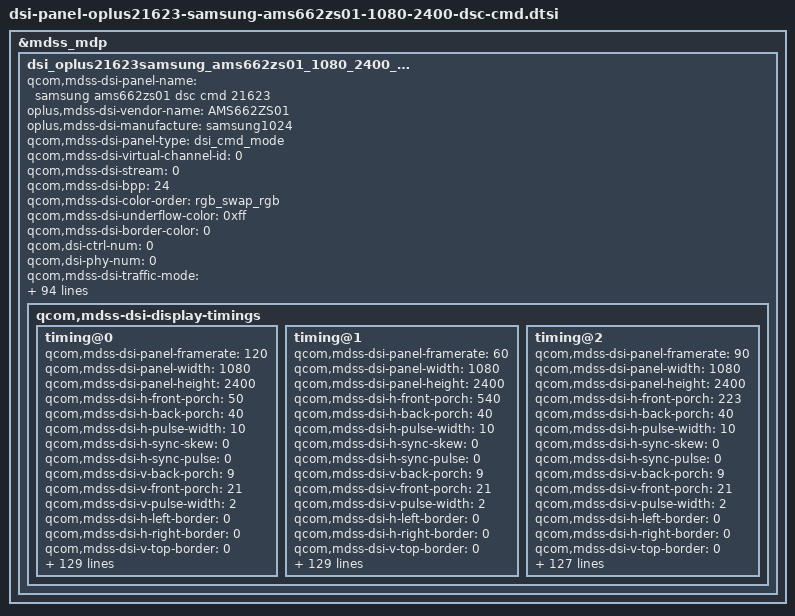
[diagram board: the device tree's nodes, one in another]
&mdss_mdp {
	dsi_oplus21623samsung_ams662zs01_1080_2400_cmd: qcom,mdss_dsi_oplus21623samsung_ams662zs01_1080_2400_cmd {
		qcom,mdss-dsi-panel-name = "samsung ams662zs01 dsc cmd 21623";
		oplus,mdss-dsi-vendor-name = "AMS662ZS01";
		oplus,mdss-dsi-manufacture = "samsung1024";
		qcom,mdss-dsi-panel-type = "dsi_cmd_mode";
		qcom,mdss-dsi-virtual-channel-id = <0>;
		qcom,mdss-dsi-stream = <0>;
		qcom,mdss-dsi-bpp = <24>;
		qcom,mdss-dsi-color-order = "rgb_swap_rgb";
		qcom,mdss-dsi-underflow-color = <0xff>;
		qcom,mdss-dsi-border-color = <0>;
		qcom,dsi-ctrl-num = <0>;
		qcom,dsi-phy-num = <0>;
		qcom,mdss-dsi-traffic-mode = "non_burst_sync_event";
		qcom,mdss-dsi-lane-map = "lane_map_0123";
		qcom,mdss-dsi-bllp-eof-power-mode;
		qcom,mdss-dsi-bllp-power-mode;
		qcom,mdss-dsi-lane-0-state;
		qcom,mdss-dsi-lane-1-state;
		qcom,mdss-dsi-lane-2-state;
		qcom,mdss-dsi-lane-3-state;
		qcom,mdss-dsi-dma-trigger = "trigger_sw";
		qcom,mdss-dsi-mdp-trigger = "none";
		qcom,mdss-dsi-reset-sequence = <1 10>, <0 10>, <1 10>;

		qcom,mdss-dsi-te-pin-select = <1>;
		qcom,mdss-dsi-te-dcs-command = <1>;
		qcom,mdss-dsi-te-check-enable;
		qcom,mdss-dsi-te-using-te-pin;
		qcom,mdss-dsi-lp11-init;
		qcom,mdss-dsi-wr-mem-start = <0x2c>;
		qcom,mdss-dsi-wr-mem-continue = <0x3c>;
		qcom,mdss-dsi-panel-hdr-enabled;
		qcom,mdss-dsi-panel-hdr-color-primaries = <15635 16450 34000 16000 13250 34500 7500 3000>;
		qcom,mdss-dsi-panel-peak-brightness = <5400000>;
		qcom,mdss-dsi-panel-blackness-level = <2000>;
		qcom,mdss-pan-physical-width-dimension = <70>;
		qcom,mdss-pan-physical-height-dimension = <153>;
		qcom,esd-check-enabled;
		qcom,mdss-dsi-panel-status-check-mode = "reg_read";
		qcom,mdss-dsi-panel-status-command = [06 01 00 01 05 00 02 0A 00
							06 01 00 01 05 00 02 05 00
							06 01 00 01 05 00 02 03 00
							06 01 00 01 05 00 02 0e 00];
		qcom,mdss-dsi-panel-status-command-state = "dsi_lp_mode";
		qcom,mdss-dsi-panel-status-value = <0x9f 0x00 0x01 0x80>;
		qcom,mdss-dsi-panel-status-read-length = <1 1 1 1>;
//		oplus,esd-err-flag-check-enabled;
		oplus,esd-err-flag-gpio = <&tlmm 100 0>;
		oplus,esd-err-trigger-polarity = <1>;
		qcom,dynamic-mode-switch-enabled;
		qcom,dynamic-mode-switch-type = "dynamic-resolution-switch-immediate";
		qcom,mdss-dsi-display-timings {
			timing@0 {
				qcom,mdss-dsi-panel-framerate = <120>;
//				qcom,mdss-dsi-panel-clockrate = <830000000>;
				qcom,mdss-dsi-panel-width = <1080>;
				qcom,mdss-dsi-panel-height = <2400>;
				qcom,mdss-dsi-h-front-porch = <50>;
				qcom,mdss-dsi-h-back-porch = <40>;
				qcom,mdss-dsi-h-pulse-width = <10>;
				qcom,mdss-dsi-h-sync-skew = <0>;
				qcom,mdss-dsi-h-sync-pulse = <0>;
				qcom,mdss-dsi-v-back-porch = <9>;
				qcom,mdss-dsi-v-front-porch = <21>;
				qcom,mdss-dsi-v-pulse-width = <2>;
				qcom,mdss-dsi-h-left-border = <0>;
				qcom,mdss-dsi-h-right-border = <0>;
				qcom,mdss-dsi-v-top-border = <0>;
				qcom,mdss-dsi-v-bottom-border = <0>;
				qcom,mdss-dsi-panel-jitter = <0x4 0x1>;

				oplus,fod-on-vblank = <0>;
				oplus,fod-off-vblank = <1>;
				qcom,mdss-dsi-timing-switch-command = [
					//120hz Transition
					39 01 00 00 00 00 03 F0 5A 5A
					39 01 00 00 00 00 03 60 08 00
					39 01 00 00 00 00 02 F7 0F
					39 01 00 00 00 00 03 F0 A5 A5
				];
				qcom,mdss-dsi-fps-switch-command = [
					39 01 00 00 00 00 03 F0 5A 5A
                                        39 01 00 00 00 00 03 B0 28 F2
                                        39 01 00 00 00 00 02 F2 CE
                                        39 01 00 00 00 00 04 B0 01 B4 65
                                        39 01 00 00 00 00 21 65 09 70 09 28 09 03 08 98 08 2C 07 BF 06 EA 06 12 05 3A 04 62 03 8B 02 B2 01 6D 00 28 00 28 00 28 
                                        39 01 00 00 00 00 04 B0 00 28 F2
                                        39 01 00 00 00 00 02 F2 C6
                                        39 01 00 00 00 00 03 60 08 00
                                        39 01 00 00 00 00 03 B0 08 F2
                                        39 01 00 00 00 00 02 F2 04
                                        39 01 00 00 00 00 02 F7 0F
                                        39 01 00 00 00 00 03 F0 A5 A5
				];
				qcom,mdss-dsi-on-command = [
					//DSC Setting
					39 01 00 00 00 00 81 9E
					11 00 00 89 30 80 09 60
					04 38 00 1E 02 1C 02 1C
					02 00 02 0E 00 20 02 E3
					00 07 00 0C 03 50 03 64
					18 00 10 F0 03 0C 20 00
					06 0B 0B 33 0E 1C 2A 38
					46 54 62 69 70 77 79 7B
					7D 7E 01 02 01 00 09 40
					09 BE 19 FC 19 FA 19 F8
					1A 38 1A 78 1A B6 2A F6
					2B 34 2B 74 3B 74 6B F4
					00 00 00 00 00 00 00 00
					00 00 00 00 00 00 00 00
					00 00 00 00 00 00 00 00
					00 00 00 00 00 00 00 00
					00 00 00 00 00 00 00 00
					39 01 00 00 00 00 02 C2 14
					39 01 00 00 00 00 02 9D 01
					//Sleep Out(11h)
					05 01 00 00 79 00 01 11
					//TE ON
					39 01 00 00 00 00 02 35 00
					//CASET/PASET Setting
					39 01 00 00 00 00 05 2A 00 00 04 37
					39 01 00 00 00 00 05 2B 00 00 09 5F
					//FQ CON Setting
					39 01 00 00 00 00 03 F0 5A 5A
					39 01 00 00 00 00 03 B0 27 F2
					39 01 00 00 00 00 02 F2 00
					39 01 00 00 00 00 03 F0 A5 A5
					//Frequency Setting
					39 01 00 00 00 00 03 F0 5A 5A
					39 01 00 00 00 00 03 60 08 00
					39 01 00 00 00 00 02 F7 0F
					39 01 00 00 00 00 03 F0 A5 A5
					/*OSC*/
					//39 01 00 00 00 00 03 F0 5A 5A
					//39 01 00 00 00 00 03 FC 5A 5A
					//39 01 00 00 00 00 03 B0 66 C5
					//39 01 00 00 00 00 03 C5 00 8C
					//39 01 00 00 00 00 03 B0 2A C5
					//39 01 00 00 00 00 05 C5 0D 10 80 45
					//39 01 00 00 00 00 03 B0 2E C5
					//39 01 00 00 00 00 03 C5 73 64
					//39 01 00 00 00 00 03 F0 A5 A5
					//39 01 00 00 00 00 03 FC A5 A5
					//BACKLIGHT
					39 01 00 00 00 00 02 53 20    //1 frame
				];

				qcom,mdss-dsi-off-command= [
					/* AOD off */
					39 01 00 00 00 00 03 F0 5A 5A
					15 01 00 00 00 00 02 91 02
					15 01 00 00 00 00 02 53 20
					39 01 00 00 00 00 03 F0 A5 A5
					05 01 00 00 0B 00 01 28
					05 01 00 00 79 00 01 10];
				qcom,mdss-dsi-post-on-backlight = [
					/* Display On */
					05 01 00 00 00 00 01 29
				];
				qcom,mdss-dsi-hbm-on-command = [
					39 01 00 00 00 00 03 F0 5A 5A
					39 01 00 00 0A 00 03 51 07 FF
					39 01 00 00 00 00 03 91 02 00
					39 01 00 00 00 00 03 B0 02 90
					39 01 00 00 00 00 02 90 1C
					/* HBM Mode ON */
					39 01 00 00 00 00 02 53 E0
					39 01 00 00 00 00 03 51 0F FF
					39 01 00 00 00 00 03 F0 A5 A5
				];
				qcom,mdss-dsi-normal-hbm-on-command = [
					39 01 00 00 00 00 03 F0 5A 5A
					39 01 00 00 0A 00 03 51 07 FF
					39 01 00 00 00 00 03 91 02 00
					39 01 00 00 00 00 03 B0 02 90
					39 01 00 00 00 00 02 90 1C
					/* HBM Mode ON */
					39 01 00 00 00 00 02 53 E0
					39 01 00 00 00 00 03 51 0F FF
					39 01 00 00 00 00 03 F0 A5 A5
				];
				qcom,mdss-dsi-hbm-off-command = [
					39 01 00 00 00 00 03 F0 5A 5A
					15 01 00 00 00 00 02 53 20
					39 01 00 00 0A 00 03 51 07 FF
					39 01 00 00 00 00 03 91 02 01
					39 01 00 00 00 00 03 B0 02 90
					39 01 00 00 00 00 02 90 18
					39 01 00 00 00 00 03 F0 A5 A5
				];
				qcom,mdss-dsi-aod-hbm-on-command = [
					39 01 00 00 00 00 03 F0 5A 5A
					15 01 00 00 00 00 02 91 02
					39 01 00 00 00 00 02 53 20
					39 01 00 00 00 00 03 F0 A5 A5
					39 01 00 00 00 00 03 F0 5A 5A
					39 01 00 00 0A 00 03 51 07 FF
					39 01 00 00 00 00 03 91 02 00
					39 01 00 00 00 00 03 B0 02 90
					39 01 00 00 00 00 02 90 1C
					/* HBM Mode ON */
					39 01 00 00 00 00 02 53 E0
					39 01 00 00 00 00 03 51 0F FF
					39 01 00 00 00 00 03 F0 A5 A5
				];
				qcom,mdss-dsi-aod-hbm-off-command = [
					39 01 00 00 00 00 03 F0 5A 5A
					15 01 00 00 00 00 02 91 02 
					15 01 00 00 00 00 02 53 20
					39 01 00 00 00 00 03 F0 A5 A5
					39 01 00 00 00 00 03 F0 5A 5A
					15 01 00 00 00 00 02 53 20
					39 01 00 00 0A 00 03 51 07 FF
					39 01 00 00 00 00 03 91 02 01
					39 01 00 00 00 00 03 B0 02 90
					39 01 00 00 00 00 02 90 18
					39 01 00 00 00 00 03 F0 A5 A5
				];
				qcom,mdss-dsi-aod-high-mode-command = [
					/* AOD 50nit */
					39 01 00 00 00 00 03 F0 5A 5A
					15 01 00 00 00 00 02 91 01
					15 01 00 00 00 00 02 53 24
					15 01 00 00 00 00 02 BB 1D
					39 01 00 00 00 00 03 F0 A5 A5
				];
				qcom,mdss-dsi-aod-low-mode-command = [
					/* AOD 10nit */
					39 01 00 00 00 00 03 F0 5A 5A
					15 01 00 00 00 00 02 91 01
					15 01 00 00 00 00 02 53 25
					15 01 00 00 00 00 02 BB 1D
					39 01 00 00 00 00 03 F0 A5 A5
				];
				qcom,mdss-dsi-lp1-command = [
					//05 01 00 00 25 00 01 28
					/*AOD on */
					39 01 00 00 00 00 03 F0 5A 5A
					15 01 00 00 00 00 02 91 01
					15 01 00 00 00 00 02 53 24
					15 01 00 00 00 00 02 BB 1D
					39 01 00 00 00 00 03 F0 A5 A5
				];
				qcom,mdss-dsi-nolp-command = [
					/* AOD off to normal*/
					39 01 00 00 00 00 03 F0 5A 5A
					15 01 00 00 00 00 02 91 02
					15 01 00 00 00 00 02 53 20
					39 01 00 00 00 00 03 F0 A5 A5
				];
				qcom,mdss-dsi-seed-off-command = [
					/* CRC OFF */
					39 01 00 00 00 00 03 F0 5A 5A
 					15 01 00 00 00 00 02 5D 00
 					15 01 00 00 00 00 02 62 01
 					39 01 00 00 00 00 03 F0 A5 A5
				];
				qcom,mdss-dsi-seed-3-command = [
					39 01 00 00 00 00 03 F0 5A 5A
					39 01 00 00 00 00 03 B0 03 8F
					39 01 00 00 00 00 02 8F 25
					39 01 00 00 00 00 03 B0 28 F2
					39 01 00 00 00 00 02 F2 CE
					39 01 00 00 00 00 04 B0 01 18 68
					39 01 00 00 00 00 0F 68 E2 1A 1A 1A 82 04 F0 80 00 00 00 00 FF 00
					39 01 00 00 00 00 04 B0 00 28 F2
					39 01 00 00 00 00 02 F2 C6
					39 01 00 00 00 00 03 F0 A5 A5
					39 01 00 00 00 00 03 F0 5A 5A
					39 01 00 00 00 00 04 72 2C 21 00
					39 01 00 00 00 00 02 F8 00
					39 01 00 00 00 00 02 5D 06
					39 01 00 00 00 00 02 62 00
					39 01 00 00 00 00 03 B0 01 62
					39 01 00 00 00 00 16 62 D3 01 00 19 Fd 00 0B 04 E2 21 E5 E4 de 06 Ec FA FD 01 FF FF FF
					39 01 00 00 18 00 04 72 2C 01 00
					39 01 00 00 00 00 03 F0 A5 A5
				];
				qcom,mdss-dsi-seed-2-command = [
					39 01 00 00 00 00 03 F0 5A 5A
					39 01 00 00 00 00 03 B0 03 8F
					39 01 00 00 00 00 02 8F 05
					39 01 00 00 00 00 03 B0 28 F2
					39 01 00 00 00 00 02 F2 CE
					39 01 00 00 00 00 04 B0 01 18 68
					39 01 00 00 00 00 0F 68 E2 1A 1A 1A 82 04 F0 80 00 00 00 00 FF 00
					39 01 00 00 00 00 04 B0 00 28 F2
					39 01 00 00 00 00 02 F2 C6
					39 01 00 00 00 00 03 F0 A5 A5
					39 01 00 00 00 00 03 F0 5A 5A
					39 01 00 00 00 00 04 72 2C 21 00
					39 01 00 00 00 00 02 F8 00
					39 01 00 00 00 00 02 5D 06
					39 01 00 00 00 00 02 62 00
					39 01 00 00 00 00 03 B0 01 62
					39 01 00 00 00 00 16 62 FF 00 00 00 FF 00 00 00 FF 00 FF FF FF 00 FF FF FF 00 FF FF FF
					39 01 00 00 18 00 04 72 2C 01 00
					39 01 00 00 00 00 03 F0 A5 A5
				];
				qcom,mdss-dsi-seed-1-command = [
					39 01 00 00 00 00 03 F0 5A 5A
					39 01 00 00 00 00 03 B0 03 8F
					39 01 00 00 00 00 02 8F 25
					39 01 00 00 00 00 03 B0 28 F2
					39 01 00 00 00 00 02 F2 CE
					39 01 00 00 00 00 04 B0 01 18 68
					39 01 00 00 00 00 0F 68 E2 1A 1A 1A 82 04 F0 80 00 00 00 00 FF 00
					39 01 00 00 00 00 04 B0 00 28 F2
					39 01 00 00 00 00 02 F2 C6
					39 01 00 00 00 00 03 F0 A5 A5
					39 01 00 00 00 00 03 F0 5A 5A
					39 01 00 00 00 00 04 72 2C 21 00
					39 01 00 00 00 00 02 F8 00
					39 01 00 00 00 00 02 5D 06
					39 01 00 00 00 00 02 62 00
					39 01 00 00 00 00 03 B0 01 62
					39 01 00 00 00 00 16 62 D3 01 00 19 Fd 00 0B 04 E2 21 E5 E4 de 06 Ec FA FD 01 FF FF FF
					39 01 00 00 18 00 04 72 2C 01 00
					39 01 00 00 00 00 03 F0 A5 A5
				];
				qcom,mdss-dsi-seed-0-command = [
					39 01 00 00 00 00 03 F0 5A 5A
					39 01 00 00 00 00 03 B0 03 8F
					39 01 00 00 00 00 02 8F 05
					39 01 00 00 00 00 03 B0 28 F2
					39 01 00 00 00 00 02 F2 CE
					39 01 00 00 00 00 04 B0 01 18 68
					39 01 00 00 00 00 0F 68 E2 1A 1A 1A 82 04 F0 80 00 00 00 00 FF 90
					39 01 00 00 00 00 04 B0 00 28 F2
					39 01 00 00 00 00 02 F2 C6
					39 01 00 00 00 00 03 F0 A5 A5
					39 01 00 00 00 00 03 F0 5A 5A
					39 01 00 00 00 00 04 72 2C 21 00
					39 01 00 00 00 00 02 F8 00
					39 01 00 00 00 00 02 5D 06
					39 01 00 00 00 00 02 62 00
					39 01 00 00 00 00 03 B0 01 62
					39 01 00 00 00 00 16 62 E5 02 00 1E F2 04 0B 06 E5 28 F3 F7 F8 08 FF EA F4 02 FF FF FF
					39 01 00 00 18 00 04 72 2C 01 00
					39 01 00 00 00 00 03 F0 A5 A5
				];
				qcom,mdss-dsi-seed-0-switch-command = [
					39 01 00 00 00 00 03 F0 5A 5A
					39 01 00 00 00 00 03 B0 03 8F
					39 01 00 00 00 00 02 8F 05
					39 01 00 00 00 00 03 B0 28 F2
					39 01 00 00 00 00 02 F2 CE
					39 01 00 00 00 00 04 B0 01 18 68
					39 01 00 00 00 00 0F 68 E2 1A 1A 1A 82 04 F0 80 00 00 00 00 FF 00
					39 01 00 00 00 00 04 B0 00 28 F2
					39 01 00 00 00 00 02 F2 C6
					39 01 00 00 00 00 03 F0 A5 A5
					39 01 00 00 00 00 03 F0 5A 5A
					39 01 00 00 00 00 04 72 2C 21 00
					39 01 00 00 00 00 02 F8 00
					39 01 00 00 00 00 02 5D 06
					39 01 00 00 00 00 02 62 00
					39 01 00 00 00 00 03 B0 01 62
					39 01 00 00 00 00 16 62 FF 00 00 00 FF 00 00 00 FF 00 FF FF FF 00 FF FF FF 00 FA FA FF
					39 01 00 00 14 00 04 72 2C 01 00
					39 01 00 00 00 00 03 F0 A5 A5
				];
                                qcom,mdss-dsi-seed-1-switch-command = [
					39 01 00 00 00 00 03 F0 5A 5A
					39 01 00 00 00 00 03 B0 03 8F
					39 01 00 00 00 00 02 8F 25
					39 01 00 00 00 00 03 B0 28 F2
					39 01 00 00 00 00 02 F2 CE
					39 01 00 00 00 00 04 B0 01 18 68
					39 01 00 00 00 00 0F 68 E2 1A 1A 1A 82 04 F0 80 00 00 00 00 FF 00
					39 01 00 00 00 00 04 B0 00 28 F2
					39 01 00 00 00 00 02 F2 C6
					39 01 00 00 00 00 03 F0 A5 A5
					39 01 00 00 00 00 03 F0 5A 5A
					39 01 00 00 00 00 04 72 2C 21 00
					39 01 00 00 00 00 02 F8 00
					39 01 00 00 00 00 02 5D 06
					39 01 00 00 00 00 02 62 00
					39 01 00 00 00 00 03 B0 01 62
					39 01 00 00 00 00 16 62 CA 0B 06 40 E9 13 0A 03 B0 48 F2 DC C4 07 C8 E9 E9 1D FA FA FF
					39 01 00 00 14 00 04 72 2C 01 00
					39 01 00 00 00 00 03 F0 A5 A5
                                ];
                                qcom,mdss-dsi-seed-2-switch-command = [
					39 01 00 00 00 00 03 F0 5A 5A
					39 01 00 00 00 00 03 B0 03 8F
					39 01 00 00 00 00 02 8F 05
					39 01 00 00 00 00 03 B0 28 F2
					39 01 00 00 00 00 02 F2 CE
					39 01 00 00 00 00 04 B0 01 18 68
					39 01 00 00 00 00 0F 68 E2 1A 1A 1A 82 04 F0 80 00 00 00 00 FF 90
					39 01 00 00 00 00 04 B0 00 28 F2
					39 01 00 00 00 00 02 F2 C6
					39 01 00 00 00 00 03 F0 A5 A5
					39 01 00 00 00 00 03 F0 5A 5A
					39 01 00 00 00 00 04 72 2C 21 00
					39 01 00 00 00 00 02 F8 00
					39 01 00 00 00 00 02 5D 06
					39 01 00 00 00 00 02 62 00
					39 01 00 00 00 00 03 B0 01 62
					39 01 00 00 00 00 16 62 D7 02 00 1E EA 04 0D 05 C8 28 F3 F7 F8 08 FF EA F4 02 FA FA FF
					39 01 00 00 14 00 04 72 2C 01 00
					39 01 00 00 00 00 03 F0 A5 A5
                                ];
				qcom,mdss-dsi-seed-0-dc-command = [
					39 01 00 00 00 00 03 F0 5A 5A
					39 01 00 00 00 00 03 B0 03 8F
					39 01 00 00 00 00 02 8F 05
					39 01 00 00 00 00 03 B0 28 F2
					39 01 00 00 00 00 02 F2 CE
					39 01 00 00 00 00 04 B0 01 18 68
					39 01 00 00 00 00 0F 68 E2 1A 1A 1A 82 04 F0 80 00 00 00 00 FF 90
					39 01 00 00 00 00 04 B0 00 28 F2
					39 01 00 00 00 00 02 F2 C6
					39 01 00 00 00 00 03 F0 A5 A5
                                        /* SEED CRC Setting Adobe*/
                                        39 01 00 00 00 00 03 F0 5A 5A
					39 01 00 00 00 00 02 5D 06
					39 01 00 00 00 00 02 62 00
					39 01 00 00 00 00 03 B0 01 62
					39 01 00 00 00 00 16 62 FF 00 00 00 FF 00 00 00 FF 00 FF FF FF 00 FF FF FF 00 FF FF FF
                                        39 01 00 00 00 00 03 F0 A5 A5
                                ];
                                qcom,mdss-dsi-seed-1-dc-command = [
					39 01 00 00 00 00 03 F0 5A 5A
					39 01 00 00 00 00 03 B0 03 8F
					39 01 00 00 00 00 02 8F 25
					39 01 00 00 00 00 03 B0 28 F2
					39 01 00 00 00 00 02 F2 CE
					39 01 00 00 00 00 04 B0 01 18 68
					39 01 00 00 00 00 0F 68 E2 1A 1A 1A 82 04 F0 80 00 00 00 00 FF 90
					39 01 00 00 00 00 04 B0 00 28 F2
					39 01 00 00 00 00 02 F2 C6
					39 01 00 00 00 00 03 F0 A5 A5
                                        /* SEED CRC Setting SRGB*/
                                        39 01 00 00 00 00 03 F0 5A 5A
                                        39 01 00 00 00 00 02 5D 06              /* SRGB */
                                        /* SEED CRC ON */
                                        39 01 00 00 00 00 02 62 00
                                        /* SEED CRC Adobe */
                                        39 01 00 00 00 00 03 B0 01 62
					39 01 00 00 00 00 16 62 CA 0B 06 40 E9 13 0A 03 B0 48 F2 DC C4 07 C8 E9 E9 1D FF FF FF
                                        39 01 00 00 00 00 03 F0 A5 A5
                                ];
                                qcom,mdss-dsi-seed-2-dc-command = [
					39 01 00 00 00 00 03 F0 5A 5A
					39 01 00 00 00 00 03 B0 03 8F
					39 01 00 00 00 00 02 8F 05
					39 01 00 00 00 00 03 B0 28 F2
					39 01 00 00 00 00 02 F2 CE
					39 01 00 00 00 00 04 B0 01 18 68
					39 01 00 00 00 00 0F 68 E2 1A 1A 1A 82 04 F0 80 00 00 00 00 FF 90
					39 01 00 00 00 00 04 B0 00 28 F2
					39 01 00 00 00 00 02 F2 C6
					39 01 00 00 00 00 03 F0 A5 A5
                                        /* SEED CRC Setting P3*/
                                        39 01 00 00 00 00 03 F0 5A 5A
					39 01 00 00 00 00 02 5D 06
					39 01 00 00 00 00 02 62 00
					39 01 00 00 00 00 03 B0 01 62
					39 01 00 00 00 00 16 62 D7 02 00 1E EA 04 0D 05 C8 28 F3 F7 F8 08 FF EA F4 02 FF FF FF
                                        39 01 00 00 00 00 03 F0 A5 A5
                                ];
				qcom,mdss-dsi-seed-0-dc-switch-command = [
					39 01 00 00 00 00 03 F0 5A 5A
					39 01 00 00 00 00 03 B0 03 8F
					39 01 00 00 00 00 02 8F 05
					39 01 00 00 00 00 03 B0 28 F2
					39 01 00 00 00 00 02 F2 CE
					39 01 00 00 00 00 04 B0 01 18 68
					39 01 00 00 00 00 0F 68 E2 1A 1A 1A 82 04 F0 80 00 00 00 00 FF 00
					39 01 00 00 00 00 04 B0 00 28 F2
					39 01 00 00 00 00 02 F2 C6
					39 01 00 00 00 00 03 F0 A5 A5
					39 01 00 00 00 00 03 F0 5A 5A
					39 01 00 00 00 00 04 72 2C 21 00
					39 01 00 00 00 00 02 F8 00
					39 01 00 00 00 00 02 5D 06
					39 01 00 00 00 00 02 62 00
					39 01 00 00 00 00 03 B0 01 62
					39 01 00 00 00 00 16 62 FF 00 00 00 FF 00 00 00 FF 00 FF FF FF 00 FF FF FF 00 FF FF FF
					39 01 00 00 14 00 04 72 2C 01 00
					39 01 00 00 00 00 03 F0 A5 A5
                                ];
                                qcom,mdss-dsi-seed-1-dc-switch-command = [
					39 01 00 00 00 00 03 F0 5A 5A
					39 01 00 00 00 00 03 B0 03 8F
					39 01 00 00 00 00 02 8F 25
					39 01 00 00 00 00 03 B0 28 F2
					39 01 00 00 00 00 02 F2 CE
					39 01 00 00 00 00 04 B0 01 18 68
					39 01 00 00 00 00 0F 68 E2 1A 1A 1A 82 04 F0 80 00 00 00 00 FF 00
					39 01 00 00 00 00 04 B0 00 28 F2
					39 01 00 00 00 00 02 F2 C6
					39 01 00 00 00 00 03 F0 A5 A5
					39 01 00 00 00 00 03 F0 5A 5A
					39 01 00 00 00 00 04 72 2C 21 00
					39 01 00 00 00 00 02 F8 00
					39 01 00 00 00 00 02 5D 06
					39 01 00 00 00 00 02 62 00
					39 01 00 00 00 00 03 B0 01 62
					39 01 00 00 00 00 16 62 CA 0B 06 40 E9 13 0A 03 B0 48 F2 DC C4 07 C8 E9 E9 1D FF FF FF
					39 01 00 00 14 00 04 72 2C 01 00
					39 01 00 00 00 00 03 F0 A5 A5
                                ];
                                qcom,mdss-dsi-seed-2-dc-switch-command = [
					39 01 00 00 00 00 03 F0 5A 5A
					39 01 00 00 00 00 03 B0 03 8F
					39 01 00 00 00 00 02 8F 05
					39 01 00 00 00 00 03 B0 28 F2
					39 01 00 00 00 00 02 F2 CE
					39 01 00 00 00 00 04 B0 01 18 68
					39 01 00 00 00 00 0F 68 E2 1A 1A 1A 82 04 F0 80 00 00 00 00 FF 90
					39 01 00 00 00 00 04 B0 00 28 F2
					39 01 00 00 00 00 02 F2 C6
					39 01 00 00 00 00 03 F0 A5 A5
					39 01 00 00 00 00 03 F0 5A 5A
					39 01 00 00 00 00 04 72 2C 21 00
					39 01 00 00 00 00 02 F8 00
					39 01 00 00 00 00 02 5D 06
					39 01 00 00 00 00 02 62 00
					39 01 00 00 00 00 03 B0 01 62
					39 01 00 00 00 00 16 62 D7 02 00 1E EA 04 0D 05 C8 28 F3 F7 F8 08 FF EA F4 02 FF FF FF
					39 01 00 00 14 00 04 72 2C 01 00
					39 01 00 00 00 00 03 F0 A5 A5
                                ];
				qcom,mdss-dsi-hbm-enter-switch-command = [
					39 01 00 00 00 00 03 F0 5A 5A
                                        39 01 00 00 0A 00 03 51 07 FF
                                        39 01 00 00 00 00 03 91 02 00
                                        39 01 00 00 00 00 03 B0 02 90
                                        39 01 00 00 00 00 02 90 1C
                                        /* HBM Mode ON */
                                        39 01 00 00 00 00 02 53 E0
                                        39 01 00 00 00 00 03 F0 A5 A5
				];
				qcom,mdss-dsi-hbm-exit-switch-command = [
					39 01 00 00 00 00 03 F0 5A 5A
                                        15 01 00 00 00 00 02 53 20
                                        39 01 00 00 0A 00 03 51 07 FF
                                        39 01 00 00 00 00 03 91 02 01
                                        39 01 00 00 00 00 03 B0 02 90
                                        39 01 00 00 00 00 02 90 18
                                        39 01 00 00 00 00 03 F0 A5 A5
				];
				qcom,mdss-dsi-osc-clk-mode0-command = [
					/*OSC 415 + 180.3*/
					39 01 00 00 00 00 03 F0 5A 5A
					39 01 00 00 00 00 03 FC 5A 5A
					39 01 00 00 00 00 03 B0 2A C5
					39 01 00 00 00 00 05 C5 0D 10 80 45
					39 01 00 00 00 00 03 B0 2E C5
					39 01 00 00 00 00 03 C5 6F 39
					39 01 00 00 00 00 03 F0 A5 A5
					39 01 00 00 00 00 03 FC A5 A5
				];
				qcom,mdss-dsi-osc-clk-mode1-command = [
					/*OSC 415 + 182.3*/
					39 01 00 00 00 00 03 F0 5A 5A
					39 01 00 00 00 00 03 FC 5A 5A
					39 01 00 00 00 00 03 B0 2A C5
					39 01 00 00 00 00 05 C5 0D 10 80 45
					39 01 00 00 00 00 03 B0 2E C5
					39 01 00 00 00 00 03 C5 70 74
					39 01 00 00 00 00 03 F0 A5 A5
					39 01 00 00 00 00 03 FC A5 A5
				];
				qcom,mdss-dsi-osc-clk-mode2-command = [
					/*OSC 400 + 180.3*/
					39 01 00 00 00 00 03 F0 5A 5A
					39 01 00 00 00 00 03 FC 5A 5A
					39 01 00 00 00 00 03 B0 2A C5
					39 01 00 00 00 00 05 C5 0D 10 80 45
					39 01 00 00 00 00 03 B0 2E C5
					39 01 00 00 00 00 03 C5 73 64
					39 01 00 00 00 00 03 F0 A5 A5
					39 01 00 00 00 00 03 FC A5 A5
				];
				qcom,mdss-dsi-osc-clk-mode3-command = [
					/*OSC 400 + 182.3*/
					39 01 00 00 00 00 03 F0 5A 5A
					39 01 00 00 00 00 03 FC 5A 5A
					39 01 00 00 00 00 03 B0 2A C5
					39 01 00 00 00 00 05 C5 0D 10 80 45
					39 01 00 00 00 00 03 B0 2E C5
					39 01 00 00 00 00 03 C5 74 AC
					39 01 00 00 00 00 03 F0 A5 A5
					39 01 00 00 00 00 03 FC A5 A5
				];
				qcom,mdss-dsi-timing-switch-command-state = "dsi_hs_mode";
				qcom,mdss-dsi-on-command-state = "dsi_lp_mode";
				qcom,mdss-dsi-off-command-state = "dsi_hs_mode";
				qcom,mdss-dsi-hbm-on-command-state = "dsi_hs_mode";
				qcom,mdss-dsi-hbm-off-command-state = "dsi_hs_mode";
				qcom,mdss-dsi-osc-clk-mode0-command-state = "dsi_hs_mode";
				qcom,mdss-dsi-osc-clk-mode1-command-state = "dsi_hs_mode";
				qcom,mdss-dsi-osc-clk-mode2-command-state = "dsi_hs_mode";
				qcom,mdss-dsi-osc-clk-mode3-command-state = "dsi_hs_mode";
				qcom,mdss-dsi-seed-0-command-state = "dsi_hs_mode";
				qcom,mdss-dsi-seed-1-command-state = "dsi_hs_mode";
				qcom,mdss-dsi-seed-2-command-state = "dsi_hs_mode";
				qcom,mdss-dsi-seed-3-command-state = "dsi_hs_mode";
				qcom,mdss-dsi-seed-0-dc-switch-command-state = "dsi_hs_mode";
				qcom,mdss-dsi-seed-1-dc-switch-command-state = "dsi_hs_mode";
				qcom,mdss-dsi-seed-2-dc-switch-command-state = "dsi_hs_mode";
				qcom,mdss-dsi-seed-0-dc-command-state = "dsi_hs_mode";
				qcom,mdss-dsi-seed-1-dc-command-state = "dsi_hs_mode";
				qcom,mdss-dsi-seed-2-dc-command-state = "dsi_hs_mode";
				qcom,mdss-dsi-seed-off-command-state = "dsi_hs_mode";
				qcom,mdss-dsi-seed-0-switch-command-state = "dsi_hs_mode";
				qcom,mdss-dsi-seed-1-switch-command-state = "dsi_hs_mode";
				qcom,mdss-dsi-seed-2-switch-command-state = "dsi_hs_mode";
				qcom,mdss-dsi-fps-switch-command-state = "dsi_hs_mode";
				qcom,compression-mode = "dsc";
				qcom,mdss-dsc-slice-height = <30>;
				qcom,mdss-dsc-slice-width = <540>;
				qcom,mdss-dsc-slice-per-pkt = <2>;
				qcom,mdss-dsc-bit-per-component = <8>;
				qcom,mdss-dsc-bit-per-pixel = <8>;
				qcom,mdss-dsc-block-prediction-enable;
			};

			timing@1 {
				qcom,mdss-dsi-panel-framerate = <60>;
//				qcom,mdss-dsi-panel-clockrate = <830000000>;
				qcom,mdss-dsi-panel-width = <1080>;
				qcom,mdss-dsi-panel-height = <2400>;
				qcom,mdss-dsi-h-front-porch = <540>;
				qcom,mdss-dsi-h-back-porch = <40>;
				qcom,mdss-dsi-h-pulse-width = <10>;
				qcom,mdss-dsi-h-sync-skew = <0>;
				qcom,mdss-dsi-h-sync-pulse = <0>;
				qcom,mdss-dsi-v-back-porch = <9>;
				qcom,mdss-dsi-v-front-porch = <21>;
				qcom,mdss-dsi-v-pulse-width = <2>;
				qcom,mdss-dsi-h-left-border = <0>;
				qcom,mdss-dsi-h-right-border = <0>;
				qcom,mdss-dsi-v-top-border = <0>;
				qcom,mdss-dsi-v-bottom-border = <0>;
				qcom,mdss-dsi-panel-jitter = <0x4 0x1>;

				oplus,fod-on-vblank = <0>;
				oplus,fod-off-vblank = <1>;
				qcom,mdss-dsi-timing-switch-command = [
					//60hz Transition
                                        39 01 00 00 00 00 03 F0 5A 5A
                                        39 01 00 00 00 00 03 60 00 00
                                        39 01 00 00 00 00 02 F7 0F
                                        39 01 00 00 11 00 03 F0 A5 A5
				];
				qcom,mdss-dsi-fps-switch-command = [
					39 01 00 00 00 00 03 F0 5A 5A
                                        39 01 00 00 00 00 03 B0 28 F2
                                        39 01 00 00 00 00 02 F2 CE
                                        39 01 00 00 00 00 04 B0 01 B4 65
                                        39 01 00 00 00 00 21 65 09 70 09 28 09 03 08 98 08 2C 07 BF 06 EA 06 12 05 3A 04 62 03 8B 02 B2 01 6D 00 28 00 28 00 28
                                        39 01 00 00 00 00 04 B0 00 28 F2
                                        39 01 00 00 00 00 02 F2 C6
                                        39 01 00 00 00 00 03 60 00 00
                                        39 01 00 00 00 00 03 B0 08 F2
                                        39 01 00 00 00 00 02 F2 04
                                        39 01 00 00 00 00 02 F7 0F
                                        39 01 00 00 11 00 03 F0 A5 A5
				];
				qcom,mdss-dsi-on-command = [
					//DSC Setting
					39 01 00 00 00 00 81 9E
					11 00 00 89 30 80 09 60
					04 38 00 1E 02 1C 02 1C
					02 00 02 0E 00 20 02 E3
					00 07 00 0C 03 50 03 64
					18 00 10 F0 03 0C 20 00
					06 0B 0B 33 0E 1C 2A 38
					46 54 62 69 70 77 79 7B
					7D 7E 01 02 01 00 09 40
					09 BE 19 FC 19 FA 19 F8
					1A 38 1A 78 1A B6 2A F6
					2B 34 2B 74 3B 74 6B F4
					00 00 00 00 00 00 00 00
					00 00 00 00 00 00 00 00
					00 00 00 00 00 00 00 00
					00 00 00 00 00 00 00 00
					00 00 00 00 00 00 00 00
					39 01 00 00 00 00 02 C2 14
					39 01 00 00 00 00 02 9D 01
					//Sleep Out(11h)
					05 01 00 00 79 00 01 11
					//TE ON
					39 01 00 00 00 00 02 35 00
					//CASET/PASET Setting
					39 01 00 00 00 00 05 2A 00 00 04 37
					39 01 00 00 00 00 05 2B 00 00 09 5F
					//FQ CON Setting
					39 01 00 00 00 00 03 F0 5A 5A
					39 01 00 00 00 00 03 B0 27 F2
					39 01 00 00 00 00 02 F2 00
					39 01 00 00 00 00 03 F0 A5 A5
					//Frequency Setting
					39 01 00 00 00 00 03 F0 5A 5A
					39 01 00 00 00 00 03 60 00 00
					39 01 00 00 00 00 02 F7 0F
					39 01 00 00 00 00 03 F0 A5 A5
					/*OSC*/
					//39 01 00 00 00 00 03 F0 5A 5A
					//39 01 00 00 00 00 03 FC 5A 5A
					//39 01 00 00 00 00 03 B0 66 C5
					//39 01 00 00 00 00 03 C5 00 8C
					//39 01 00 00 00 00 03 B0 2A C5
					//39 01 00 00 00 00 05 C5 0D 10 80 45
					//39 01 00 00 00 00 03 B0 2E C5
					//39 01 00 00 00 00 03 C5 73 64
					//39 01 00 00 00 00 03 F0 A5 A5
					//39 01 00 00 00 00 03 FC A5 A5
					//BACKLIGHT
					39 01 00 00 00 00 02 53 20    //1 frame
				];

				qcom,mdss-dsi-off-command= [
					/* AOD off */
					39 01 00 00 00 00 03 F0 5A 5A
					15 01 00 00 00 00 02 91 02
					15 01 00 00 00 00 02 53 20
					39 01 00 00 00 00 03 F0 A5 A5
					05 01 00 00 0B 00 01 28
					05 01 00 00 79 00 01 10];
				qcom,mdss-dsi-post-on-backlight = [
					/* Display On */
					05 01 00 00 00 00 01 29
				];
				qcom,mdss-dsi-hbm-on-command = [
					39 01 00 00 00 00 03 F0 5A 5A
					39 01 00 00 0A 00 03 51 07 FF
					39 01 00 00 00 00 03 91 02 00
					39 01 00 00 00 00 03 B0 02 90
					39 01 00 00 00 00 02 90 1C
					/* HBM Mode ON */
					39 01 00 00 00 00 02 53 E0
					39 01 00 00 00 00 03 51 0F FF
					39 01 00 00 00 00 03 F0 A5 A5
				];
				qcom,mdss-dsi-normal-hbm-on-command = [
					39 01 00 00 00 00 03 F0 5A 5A
					39 01 00 00 14 00 03 51 07 FF
					39 01 00 00 00 00 03 91 02 00
					39 01 00 00 00 00 03 B0 02 90
					39 01 00 00 00 00 02 90 1C
					/* HBM Mode ON */
					39 01 00 00 00 00 02 53 E0
					39 01 00 00 00 00 03 51 0F FF
					39 01 00 00 00 00 03 F0 A5 A5
				];
				qcom,mdss-dsi-hbm-off-command = [
					39 01 00 00 00 00 03 F0 5A 5A
					15 01 00 00 00 00 02 53 20
					39 01 00 00 14 00 03 51 07 FF
					39 01 00 00 00 00 03 91 02 01
					39 01 00 00 00 00 03 B0 02 90
					39 01 00 00 00 00 02 90 18
					39 01 00 00 00 00 03 F0 A5 A5
				];
				qcom,mdss-dsi-aod-hbm-on-command = [
					39 01 00 00 00 00 03 F0 5A 5A
                                        15 01 00 00 00 00 02 91 02
                                        39 01 00 00 00 00 02 53 20
                                        39 01 00 00 00 00 03 F0 A5 A5
					39 01 00 00 00 00 03 F0 5A 5A
					39 01 00 00 14 00 03 51 07 FF
					39 01 00 00 00 00 03 91 02 00
					39 01 00 00 00 00 03 B0 02 90
					39 01 00 00 00 00 02 90 1C
					/* HBM Mode ON */
					39 01 00 00 00 00 02 53 E0
					39 01 00 00 00 00 03 51 0F FF
					39 01 00 00 00 00 03 F0 A5 A5
				];
				qcom,mdss-dsi-aod-hbm-off-command = [
					39 01 00 00 00 00 03 F0 5A 5A
					15 01 00 00 00 00 02 91 02 
					15 01 00 00 00 00 02 53 20
					39 01 00 00 00 00 03 F0 A5 A5
					39 01 00 00 00 00 03 F0 5A 5A
					15 01 00 00 00 00 02 53 20
					39 01 00 00 0A 00 03 51 07 FF
					39 01 00 00 00 00 03 91 02 01
					39 01 00 00 00 00 03 B0 02 90
					39 01 00 00 00 00 02 90 18
					39 01 00 00 00 00 03 F0 A5 A5
				];
				qcom,mdss-dsi-aod-high-mode-command = [
					/* AOD 50nit */
					39 01 00 00 00 00 03 F0 5A 5A
					15 01 00 00 00 00 02 91 01
					15 01 00 00 00 00 02 53 24
					15 01 00 00 00 00 02 BB 1D
					39 01 00 00 00 00 03 F0 A5 A5
				];
				qcom,mdss-dsi-aod-low-mode-command = [
					/* AOD 10nit */
					39 01 00 00 00 00 03 F0 5A 5A
					15 01 00 00 00 00 02 91 01
					15 01 00 00 00 00 02 53 25
					15 01 00 00 00 00 02 BB 1D
					39 01 00 00 00 00 03 F0 A5 A5
				];
				qcom,mdss-dsi-lp1-command = [
					//05 01 00 00 25 00 01 28
					/*AOD on */
					39 01 00 00 00 00 03 F0 5A 5A
					15 01 00 00 00 00 02 91 01
					15 01 00 00 00 00 02 53 24
					15 01 00 00 00 00 02 BB 1D
					39 01 00 00 00 00 03 F0 A5 A5
				];
				qcom,mdss-dsi-nolp-command = [
					/* AOD off to normal*/
					39 01 00 00 00 00 03 F0 5A 5A
					15 01 00 00 00 00 02 91 02
					15 01 00 00 00 00 02 53 20
					39 01 00 00 00 00 03 F0 A5 A5
				];
                                qcom,mdss-dsi-seed-off-command = [
                                        /* CRC OFF */
                                        39 01 00 00 00 00 03 F0 5A 5A
                                        15 01 00 00 00 00 02 5D 00
                                        15 01 00 00 00 00 02 62 01
                                        39 01 00 00 00 00 03 F0 A5 A5
                                ];
				qcom,mdss-dsi-seed-3-command = [
					39 01 00 00 00 00 03 F0 5A 5A
					39 01 00 00 00 00 03 B0 03 8F
					39 01 00 00 00 00 02 8F 25
					39 01 00 00 00 00 03 B0 28 F2
					39 01 00 00 00 00 02 F2 CE
					39 01 00 00 00 00 04 B0 01 18 68
					39 01 00 00 00 00 0F 68 E2 1A 1A 1A 82 04 F0 80 00 00 00 00 FF 00
					39 01 00 00 00 00 04 B0 00 28 F2
					39 01 00 00 00 00 02 F2 C6
					39 01 00 00 00 00 03 F0 A5 A5
					39 01 00 00 00 00 03 F0 5A 5A
					39 01 00 00 00 00 04 72 2C 21 00
					39 01 00 00 00 00 02 F8 00
					39 01 00 00 00 00 02 5D 06
					39 01 00 00 00 00 02 62 00
					39 01 00 00 00 00 03 B0 01 62
					39 01 00 00 00 00 16 62 D3 01 00 19 Fd 00 0B 04 E2 21 E5 E4 de 06 Ec FA FD 01 FF FF FF
					39 01 00 00 18 00 04 72 2C 01 00
					39 01 00 00 00 00 03 F0 A5 A5
				];
				qcom,mdss-dsi-seed-2-command = [
					39 01 00 00 00 00 03 F0 5A 5A
					39 01 00 00 00 00 03 B0 03 8F
					39 01 00 00 00 00 02 8F 05
					39 01 00 00 00 00 03 B0 28 F2
					39 01 00 00 00 00 02 F2 CE
					39 01 00 00 00 00 04 B0 01 18 68
					39 01 00 00 00 00 0F 68 E2 1A 1A 1A 82 04 F0 80 00 00 00 00 FF 00
					39 01 00 00 00 00 04 B0 00 28 F2
					39 01 00 00 00 00 02 F2 C6
					39 01 00 00 00 00 03 F0 A5 A5
					39 01 00 00 00 00 03 F0 5A 5A
					39 01 00 00 00 00 04 72 2C 21 00
					39 01 00 00 00 00 02 F8 00
					39 01 00 00 00 00 02 5D 06
					39 01 00 00 00 00 02 62 00
					39 01 00 00 00 00 03 B0 01 62
					39 01 00 00 00 00 16 62 FF 00 00 00 FF 00 00 00 FF 00 FF FF FF 00 FF FF FF 00 FF FF FF
					39 01 00 00 18 00 04 72 2C 01 00
					39 01 00 00 00 00 03 F0 A5 A5
				];
				qcom,mdss-dsi-seed-1-command = [
					39 01 00 00 00 00 03 F0 5A 5A
					39 01 00 00 00 00 03 B0 03 8F
					39 01 00 00 00 00 02 8F 25
					39 01 00 00 00 00 03 B0 28 F2
					39 01 00 00 00 00 02 F2 CE
					39 01 00 00 00 00 04 B0 01 18 68
					39 01 00 00 00 00 0F 68 E2 1A 1A 1A 82 04 F0 80 00 00 00 00 FF 00
					39 01 00 00 00 00 04 B0 00 28 F2
					39 01 00 00 00 00 02 F2 C6
					39 01 00 00 00 00 03 F0 A5 A5
					39 01 00 00 00 00 03 F0 5A 5A
					39 01 00 00 00 00 04 72 2C 21 00
					39 01 00 00 00 00 02 F8 00
					39 01 00 00 00 00 02 5D 06
					39 01 00 00 00 00 02 62 00
					39 01 00 00 00 00 03 B0 01 62
					39 01 00 00 00 00 16 62 D3 01 00 19 Fd 00 0B 04 E2 21 E5 E4 de 06 Ec FA FD 01 FF FF FF
					39 01 00 00 18 00 04 72 2C 01 00
					39 01 00 00 00 00 03 F0 A5 A5
				];
				qcom,mdss-dsi-seed-0-command = [
					39 01 00 00 00 00 03 F0 5A 5A
					39 01 00 00 00 00 03 B0 03 8F
					39 01 00 00 00 00 02 8F 05
					39 01 00 00 00 00 03 B0 28 F2
					39 01 00 00 00 00 02 F2 CE
					39 01 00 00 00 00 04 B0 01 18 68
					39 01 00 00 00 00 0F 68 E2 1A 1A 1A 82 04 F0 80 00 00 00 00 FF 90
					39 01 00 00 00 00 04 B0 00 28 F2
					39 01 00 00 00 00 02 F2 C6
					39 01 00 00 00 00 03 F0 A5 A5
					39 01 00 00 00 00 03 F0 5A 5A
					39 01 00 00 00 00 04 72 2C 21 00
					39 01 00 00 00 00 02 F8 00
					39 01 00 00 00 00 02 5D 06
					39 01 00 00 00 00 02 62 00
					39 01 00 00 00 00 03 B0 01 62
					39 01 00 00 00 00 16 62 E5 02 00 1E F2 04 0B 06 E5 28 F3 F7 F8 08 FF EA F4 02 FF FF FF
					39 01 00 00 18 00 04 72 2C 01 00
					39 01 00 00 00 00 03 F0 A5 A5
				];
				qcom,mdss-dsi-seed-0-switch-command = [
					39 01 00 00 00 00 03 F0 5A 5A
					39 01 00 00 00 00 03 B0 03 8F
					39 01 00 00 00 00 02 8F 05
					39 01 00 00 00 00 03 B0 28 F2
					39 01 00 00 00 00 02 F2 CE
					39 01 00 00 00 00 04 B0 01 18 68
					39 01 00 00 00 00 0F 68 E2 1A 1A 1A 82 04 F0 80 00 00 00 00 FF 00
					39 01 00 00 00 00 04 B0 00 28 F2
					39 01 00 00 00 00 02 F2 C6
					39 01 00 00 00 00 03 F0 A5 A5
					39 01 00 00 00 00 03 F0 5A 5A
					39 01 00 00 00 00 04 72 2C 21 00
					39 01 00 00 00 00 02 F8 00
					39 01 00 00 00 00 02 5D 06
					39 01 00 00 00 00 02 62 00
					39 01 00 00 00 00 03 B0 01 62
					39 01 00 00 00 00 16 62 FF 00 00 00 FF 00 00 00 FF 00 FF FF FF 00 FF FF FF 00 FA FA FF
					39 01 00 00 14 00 04 72 2C 01 00
					39 01 00 00 00 00 03 F0 A5 A5
				];
                                qcom,mdss-dsi-seed-1-switch-command = [
					39 01 00 00 00 00 03 F0 5A 5A
					39 01 00 00 00 00 03 B0 03 8F
					39 01 00 00 00 00 02 8F 25
					39 01 00 00 00 00 03 B0 28 F2
					39 01 00 00 00 00 02 F2 CE
					39 01 00 00 00 00 04 B0 01 18 68
					39 01 00 00 00 00 0F 68 E2 1A 1A 1A 82 04 F0 80 00 00 00 00 FF 00
					39 01 00 00 00 00 04 B0 00 28 F2
					39 01 00 00 00 00 02 F2 C6
					39 01 00 00 00 00 03 F0 A5 A5
					39 01 00 00 00 00 03 F0 5A 5A
					39 01 00 00 00 00 04 72 2C 21 00
					39 01 00 00 00 00 02 F8 00
					39 01 00 00 00 00 02 5D 06
					39 01 00 00 00 00 02 62 00
					39 01 00 00 00 00 03 B0 01 62
					39 01 00 00 00 00 16 62 CA 0B 06 40 E9 13 0A 03 B0 48 F2 DC C4 07 C8 E9 E9 1D FA FA FF
					39 01 00 00 14 00 04 72 2C 01 00
					39 01 00 00 00 00 03 F0 A5 A5
                                ];
                                qcom,mdss-dsi-seed-2-switch-command = [
					39 01 00 00 00 00 03 F0 5A 5A
					39 01 00 00 00 00 03 B0 03 8F
					39 01 00 00 00 00 02 8F 05
					39 01 00 00 00 00 03 B0 28 F2
					39 01 00 00 00 00 02 F2 CE
					39 01 00 00 00 00 04 B0 01 18 68
					39 01 00 00 00 00 0F 68 E2 1A 1A 1A 82 04 F0 80 00 00 00 00 FF 90
					39 01 00 00 00 00 04 B0 00 28 F2
					39 01 00 00 00 00 02 F2 C6
					39 01 00 00 00 00 03 F0 A5 A5
					39 01 00 00 00 00 03 F0 5A 5A
					39 01 00 00 00 00 04 72 2C 21 00
					39 01 00 00 00 00 02 F8 00
					39 01 00 00 00 00 02 5D 06
					39 01 00 00 00 00 02 62 00
					39 01 00 00 00 00 03 B0 01 62
					39 01 00 00 00 00 16 62 D7 02 00 1E EA 04 0D 05 C8 28 F3 F7 F8 08 FF EA F4 02 FA FA FF
					39 01 00 00 14 00 04 72 2C 01 00
					39 01 00 00 00 00 03 F0 A5 A5
                                ];
				qcom,mdss-dsi-seed-0-dc-command = [
					39 01 00 00 00 00 03 F0 5A 5A
					39 01 00 00 00 00 03 B0 03 8F
					39 01 00 00 00 00 02 8F 05
					39 01 00 00 00 00 03 B0 28 F2
					39 01 00 00 00 00 02 F2 CE
					39 01 00 00 00 00 04 B0 01 18 68
					39 01 00 00 00 00 0F 68 E2 1A 1A 1A 82 04 F0 80 00 00 00 00 FF 90
					39 01 00 00 00 00 04 B0 00 28 F2
					39 01 00 00 00 00 02 F2 C6
					39 01 00 00 00 00 03 F0 A5 A5
                                        /* SEED CRC Setting Adobe*/
                                        39 01 00 00 00 00 03 F0 5A 5A
					39 01 00 00 00 00 02 5D 06
					39 01 00 00 00 00 02 62 00
					39 01 00 00 00 00 03 B0 01 62
					39 01 00 00 00 00 16 62 FF 00 00 00 FF 00 00 00 FF 00 FF FF FF 00 FF FF FF 00 FF FF FF
                                        39 01 00 00 00 00 03 F0 A5 A5
                                ];
                                qcom,mdss-dsi-seed-1-dc-command = [
					39 01 00 00 00 00 03 F0 5A 5A
					39 01 00 00 00 00 03 B0 03 8F
					39 01 00 00 00 00 02 8F 25
					39 01 00 00 00 00 03 B0 28 F2
					39 01 00 00 00 00 02 F2 CE
					39 01 00 00 00 00 04 B0 01 18 68
					39 01 00 00 00 00 0F 68 E2 1A 1A 1A 82 04 F0 80 00 00 00 00 FF 90
					39 01 00 00 00 00 04 B0 00 28 F2
					39 01 00 00 00 00 02 F2 C6
					39 01 00 00 00 00 03 F0 A5 A5
                                        /* SEED CRC Setting SRGB*/
                                        39 01 00 00 00 00 03 F0 5A 5A
                                        39 01 00 00 00 00 02 5D 06              /* SRGB */
                                        /* SEED CRC ON */
                                        39 01 00 00 00 00 02 62 00
                                        /* SEED CRC Adobe */
                                        39 01 00 00 00 00 03 B0 01 62
					39 01 00 00 00 00 16 62 CA 0B 06 40 E9 13 0A 03 B0 48 F2 DC C4 07 C8 E9 E9 1D FF FF FF
                                        39 01 00 00 00 00 03 F0 A5 A5
                                ];
                                qcom,mdss-dsi-seed-2-dc-command = [
					39 01 00 00 00 00 03 F0 5A 5A
					39 01 00 00 00 00 03 B0 03 8F
					39 01 00 00 00 00 02 8F 05
					39 01 00 00 00 00 03 B0 28 F2
					39 01 00 00 00 00 02 F2 CE
					39 01 00 00 00 00 04 B0 01 18 68
					39 01 00 00 00 00 0F 68 E2 1A 1A 1A 82 04 F0 80 00 00 00 00 FF 90
					39 01 00 00 00 00 04 B0 00 28 F2
					39 01 00 00 00 00 02 F2 C6
					39 01 00 00 00 00 03 F0 A5 A5
                                        /* SEED CRC Setting P3*/
                                        39 01 00 00 00 00 03 F0 5A 5A
					39 01 00 00 00 00 02 5D 06
					39 01 00 00 00 00 02 62 00
					39 01 00 00 00 00 03 B0 01 62
					39 01 00 00 00 00 16 62 D7 02 00 1E EA 04 0D 05 C8 28 F3 F7 F8 08 FF EA F4 02 FF FF FF
                                        39 01 00 00 00 00 03 F0 A5 A5
                                ];
				qcom,mdss-dsi-seed-0-dc-switch-command = [
					39 01 00 00 00 00 03 F0 5A 5A
					39 01 00 00 00 00 03 B0 03 8F
					39 01 00 00 00 00 02 8F 05
					39 01 00 00 00 00 03 B0 28 F2
					39 01 00 00 00 00 02 F2 CE
					39 01 00 00 00 00 04 B0 01 18 68
					39 01 00 00 00 00 0F 68 E2 1A 1A 1A 82 04 F0 80 00 00 00 00 FF 00
					39 01 00 00 00 00 04 B0 00 28 F2
					39 01 00 00 00 00 02 F2 C6
					39 01 00 00 00 00 03 F0 A5 A5
					39 01 00 00 00 00 03 F0 5A 5A
					39 01 00 00 00 00 04 72 2C 21 00
					39 01 00 00 00 00 02 F8 00
					39 01 00 00 00 00 02 5D 06
					39 01 00 00 00 00 02 62 00
					39 01 00 00 00 00 03 B0 01 62
					39 01 00 00 00 00 16 62 FF 00 00 00 FF 00 00 00 FF 00 FF FF FF 00 FF FF FF 00 FF FF FF
					39 01 00 00 14 00 04 72 2C 01 00
					39 01 00 00 00 00 03 F0 A5 A5
                                ];
                                qcom,mdss-dsi-seed-1-dc-switch-command = [
					39 01 00 00 00 00 03 F0 5A 5A
					39 01 00 00 00 00 03 B0 03 8F
					39 01 00 00 00 00 02 8F 25
					39 01 00 00 00 00 03 B0 28 F2
					39 01 00 00 00 00 02 F2 CE
					39 01 00 00 00 00 04 B0 01 18 68
					39 01 00 00 00 00 0F 68 E2 1A 1A 1A 82 04 F0 80 00 00 00 00 FF 00
					39 01 00 00 00 00 04 B0 00 28 F2
					39 01 00 00 00 00 02 F2 C6
					39 01 00 00 00 00 03 F0 A5 A5
					39 01 00 00 00 00 03 F0 5A 5A
					39 01 00 00 00 00 04 72 2C 21 00
					39 01 00 00 00 00 02 F8 00
					39 01 00 00 00 00 02 5D 06
					39 01 00 00 00 00 02 62 00
					39 01 00 00 00 00 03 B0 01 62
					39 01 00 00 00 00 16 62 CA 0B 06 40 E9 13 0A 03 B0 48 F2 DC C4 07 C8 E9 E9 1D FF FF FF
					39 01 00 00 14 00 04 72 2C 01 00
					39 01 00 00 00 00 03 F0 A5 A5
                                ];
                                qcom,mdss-dsi-seed-2-dc-switch-command = [
					39 01 00 00 00 00 03 F0 5A 5A
					39 01 00 00 00 00 03 B0 03 8F
					39 01 00 00 00 00 02 8F 05
					39 01 00 00 00 00 03 B0 28 F2
					39 01 00 00 00 00 02 F2 CE
					39 01 00 00 00 00 04 B0 01 18 68
					39 01 00 00 00 00 0F 68 E2 1A 1A 1A 82 04 F0 80 00 00 00 00 FF 90
					39 01 00 00 00 00 04 B0 00 28 F2
					39 01 00 00 00 00 02 F2 C6
					39 01 00 00 00 00 03 F0 A5 A5
					39 01 00 00 00 00 03 F0 5A 5A
					39 01 00 00 00 00 04 72 2C 21 00
					39 01 00 00 00 00 02 F8 00
					39 01 00 00 00 00 02 5D 06
					39 01 00 00 00 00 02 62 00
					39 01 00 00 00 00 03 B0 01 62
					39 01 00 00 00 00 16 62 D7 02 00 1E EA 04 0D 05 C8 28 F3 F7 F8 08 FF EA F4 02 FF FF FF
					39 01 00 00 14 00 04 72 2C 01 00
					39 01 00 00 00 00 03 F0 A5 A5
                                ];
				qcom,mdss-dsi-hbm-enter-switch-command = [
					39 01 00 00 00 00 03 F0 5A 5A
                                        39 01 00 00 14 00 03 51 07 FF
                                        39 01 00 00 00 00 03 91 02 00
                                        39 01 00 00 00 00 03 B0 02 90
                                        39 01 00 00 00 00 02 90 1C
                                        /* HBM Mode ON */
                                        39 01 00 00 00 00 02 53 E0
                                        39 01 00 00 00 00 03 F0 A5 A5
				];
				qcom,mdss-dsi-hbm-exit-switch-command = [
					39 01 00 00 00 00 03 F0 5A 5A
                                        15 01 00 00 00 00 02 53 20
                                        39 01 00 00 14 00 03 51 07 FF
                                        39 01 00 00 00 00 03 91 02 01
                                        39 01 00 00 00 00 03 B0 02 90
                                        39 01 00 00 00 00 02 90 18
                                        39 01 00 00 00 00 03 F0 A5 A5
				];
				qcom,mdss-dsi-osc-clk-mode0-command = [
					/*OSC 415 + 180.3*/
					39 01 00 00 00 00 03 F0 5A 5A
					39 01 00 00 00 00 03 FC 5A 5A
					39 01 00 00 00 00 03 B0 2A C5
					39 01 00 00 00 00 05 C5 0D 10 80 45
					39 01 00 00 00 00 03 B0 2E C5
					39 01 00 00 00 00 03 C5 6F 39
					39 01 00 00 00 00 03 F0 A5 A5
					39 01 00 00 00 00 03 FC A5 A5
				];
				qcom,mdss-dsi-osc-clk-mode1-command = [
					/*OSC 415 + 182.3*/
					39 01 00 00 00 00 03 F0 5A 5A
					39 01 00 00 00 00 03 FC 5A 5A
					39 01 00 00 00 00 03 B0 2A C5
					39 01 00 00 00 00 05 C5 0D 10 80 45
					39 01 00 00 00 00 03 B0 2E C5
					39 01 00 00 00 00 03 C5 70 74
					39 01 00 00 00 00 03 F0 A5 A5
					39 01 00 00 00 00 03 FC A5 A5
				];
				qcom,mdss-dsi-osc-clk-mode2-command = [
					/*OSC 400 + 180.3*/
					39 01 00 00 00 00 03 F0 5A 5A
					39 01 00 00 00 00 03 FC 5A 5A
					39 01 00 00 00 00 03 B0 2A C5
					39 01 00 00 00 00 05 C5 0D 10 80 45
					39 01 00 00 00 00 03 B0 2E C5
					39 01 00 00 00 00 03 C5 73 64
					39 01 00 00 00 00 03 F0 A5 A5
					39 01 00 00 00 00 03 FC A5 A5
				];
				qcom,mdss-dsi-osc-clk-mode3-command = [
					/*OSC 400 + 182.3*/
					39 01 00 00 00 00 03 F0 5A 5A
					39 01 00 00 00 00 03 FC 5A 5A
					39 01 00 00 00 00 03 B0 2A C5
					39 01 00 00 00 00 05 C5 0D 10 80 45
					39 01 00 00 00 00 03 B0 2E C5
					39 01 00 00 00 00 03 C5 74 AC
					39 01 00 00 00 00 03 F0 A5 A5
					39 01 00 00 00 00 03 FC A5 A5
				];
				qcom,mdss-dsi-timing-switch-command-state = "dsi_hs_mode";
				qcom,mdss-dsi-on-command-state = "dsi_lp_mode";
				qcom,mdss-dsi-off-command-state = "dsi_hs_mode";
				qcom,mdss-dsi-hbm-on-command-state = "dsi_hs_mode";
				qcom,mdss-dsi-hbm-off-command-state = "dsi_hs_mode";
				qcom,mdss-dsi-osc-clk-mode0-command-state = "dsi_hs_mode";
				qcom,mdss-dsi-osc-clk-mode1-command-state = "dsi_hs_mode";
				qcom,mdss-dsi-osc-clk-mode2-command-state = "dsi_hs_mode";
				qcom,mdss-dsi-osc-clk-mode3-command-state = "dsi_hs_mode";
				qcom,mdss-dsi-seed-0-command-state = "dsi_hs_mode";
				qcom,mdss-dsi-seed-1-command-state = "dsi_hs_mode";
				qcom,mdss-dsi-seed-2-command-state = "dsi_hs_mode";
				qcom,mdss-dsi-seed-3-command-state = "dsi_hs_mode";
				qcom,mdss-dsi-seed-0-dc-switch-command-state = "dsi_hs_mode";
				qcom,mdss-dsi-seed-1-dc-switch-command-state = "dsi_hs_mode";
				qcom,mdss-dsi-seed-2-dc-switch-command-state = "dsi_hs_mode";
				qcom,mdss-dsi-seed-0-dc-command-state = "dsi_hs_mode";
				qcom,mdss-dsi-seed-1-dc-command-state = "dsi_hs_mode";
				qcom,mdss-dsi-seed-2-dc-command-state = "dsi_hs_mode";
				qcom,mdss-dsi-seed-0-switch-command-state = "dsi_hs_mode";
				qcom,mdss-dsi-seed-1-switch-command-state = "dsi_hs_mode";
				qcom,mdss-dsi-seed-2-switch-command-state = "dsi_hs_mode";
				qcom,mdss-dsi-seed-off-command-state = "dsi_hs_mode";
				qcom,mdss-dsi-fps-switch-command-state = "dsi_hs_mode";
				qcom,compression-mode = "dsc";
				qcom,mdss-dsc-slice-height = <30>;
				qcom,mdss-dsc-slice-width = <540>;
				qcom,mdss-dsc-slice-per-pkt = <2>;
				qcom,mdss-dsc-bit-per-component = <8>;
				qcom,mdss-dsc-bit-per-pixel = <8>;
				qcom,mdss-dsc-block-prediction-enable;
			};
			timing@2 {
				qcom,mdss-dsi-panel-framerate = <90>;
				//qcom,mdss-dsi-panel-clockrate = <830000000>;
				qcom,mdss-dsi-panel-width = <1080>;
				qcom,mdss-dsi-panel-height = <2400>;
				qcom,mdss-dsi-h-front-porch = <223>;
				qcom,mdss-dsi-h-back-porch = <40>;
				qcom,mdss-dsi-h-pulse-width = <10>;
				qcom,mdss-dsi-h-sync-skew = <0>;
				qcom,mdss-dsi-h-sync-pulse = <0>;
				qcom,mdss-dsi-v-back-porch = <9>;
				qcom,mdss-dsi-v-front-porch = <21>;
				qcom,mdss-dsi-v-pulse-width = <2>;
				qcom,mdss-dsi-h-left-border = <0>;
				qcom,mdss-dsi-h-right-border = <0>;
				qcom,mdss-dsi-v-top-border = <0>;
				qcom,mdss-dsi-v-bottom-border = <0>;
				qcom,mdss-dsi-panel-jitter = <0x4 0x1>;

				oplus,fod-on-vblank = <0>;
				oplus,fod-off-vblank = <1>;
				/*qcom,mdss-dsi-timing-switch-command = [
					//90hz Transition
                                        39 01 00 00 00 00 03 F0 5A 5A
                                        39 01 00 00 00 00 03 B0 27 2F
                                        39 01 00 00 00 00 02 2F 00
                                        39 01 00 00 00 00 03 B0 28 F2
                                        39 01 00 00 00 00 02 F2 CE
                                        39 01 00 00 00 00 04 B0 01 B4 65
                                        39 01 00 00 00 00 21 65 0A 20 09 EC 09 AB 09 37 08 C0 08 4E 07 60 06 7D 05 8F 04 AC 03 BE 02 DB 01 87 00 34 00 34 00 34
                                        39 01 00 00 00 00 04 B0 00 28 F2
                                        39 01 00 00 00 00 02 F2 C6
                                        39 01 00 00 00 00 03 60 00 04
                                        39 01 00 00 00 00 03 B0 08 F2
				];*/
				qcom,mdss-dsi-fps-switch-command = [
					39 01 00 00 00 00 03 F0 5A 5A
                                        39 01 00 00 00 00 03 B0 28 F2
                                        39 01 00 00 00 00 02 F2 CE
                                        39 01 00 00 00 00 04 B0 01 B4 65
                                        39 01 00 00 00 00 21 65 0A 20 09 EC 09 AB 09 37 08 C0 08 4E 07 60 06 7D 05 8F 04 AC 03 BE 02 DB 01 87 00 34 00 34 00 34
                                        39 01 00 00 00 00 04 B0 00 28 F2
                                        39 01 00 00 00 00 02 F2 C6
                                        39 01 00 00 00 00 03 60 00 04
                                        39 01 00 00 00 00 03 B0 08 F2
					39 01 00 00 00 00 02 F2 B4
					39 01 00 00 00 00 02 F7 0F
					39 01 00 00 0C 00 03 F0 A5 A5
				];
				qcom,mdss-dsi-on-command = [
					//DSC Setting
					39 01 00 00 00 00 81 9E
					11 00 00 89 30 80 09 60
					04 38 00 1E 02 1C 02 1C
					02 00 02 0E 00 20 02 E3
					00 07 00 0C 03 50 03 64
					18 00 10 F0 03 0C 20 00
					06 0B 0B 33 0E 1C 2A 38
					46 54 62 69 70 77 79 7B
					7D 7E 01 02 01 00 09 40
					09 BE 19 FC 19 FA 19 F8
					1A 38 1A 78 1A B6 2A F6
					2B 34 2B 74 3B 74 6B F4
					00 00 00 00 00 00 00 00
					00 00 00 00 00 00 00 00
					00 00 00 00 00 00 00 00
					00 00 00 00 00 00 00 00
					00 00 00 00 00 00 00 00
					39 01 00 00 00 00 02 C2 14
					39 01 00 00 00 00 02 9D 01
					//Sleep Out(11h)
					05 01 00 00 79 00 01 11
					//TE ON
					39 01 00 00 00 00 02 35 00
					//CASET/PASET Setting
					39 01 00 00 00 00 05 2A 00 00 04 37
					39 01 00 00 00 00 05 2B 00 00 09 5F
					//FQ CON Setting
					39 01 00 00 00 00 03 F0 5A 5A
					39 01 00 00 00 00 03 B0 27 F2
					39 01 00 00 00 00 02 F2 00
					39 01 00 00 00 00 03 F0 A5 A5
					//Frequency Setting
					39 01 00 00 00 00 03 F0 5A 5A
                                        39 01 00 00 00 00 03 B0 28 F2
                                        39 01 00 00 00 00 02 F2 CE
                                        39 01 00 00 00 00 04 B0 01 B4 65
                                        39 01 00 00 00 00 21 65 0A 20 09 EC 09 AB 09 37 08 C0 08 4E 07 60 06 7D 05 8F 04 AC 03 BE 02 DB 01 87 00 34 00 34 00 34
                                        39 01 00 00 00 00 04 B0 00 28 F2
                                        39 01 00 00 00 00 02 F2 C6
                                        39 01 00 00 00 00 03 60 00 04
                                        39 01 00 00 00 00 03 B0 08 F2
                                        39 01 00 00 00 00 02 F2 B4
                                        39 01 00 00 00 00 02 F7 0F
                                        39 01 00 00 00 00 03 F0 A5 A5
					/*OSC*/
					//39 01 00 00 00 00 03 F0 5A 5A
					//39 01 00 00 00 00 03 FC 5A 5A
					//39 01 00 00 00 00 03 B0 66 C5
					//39 01 00 00 00 00 03 C5 00 8C
					//39 01 00 00 00 00 03 B0 2A C5
					//39 01 00 00 00 00 05 C5 0D 10 80 45
					//39 01 00 00 00 00 03 B0 2E C5
					//39 01 00 00 00 00 03 C5 73 64
					//39 01 00 00 00 00 03 F0 A5 A5
					//39 01 00 00 00 00 03 FC A5 A5
					//BACKLIGHT
					39 01 00 00 00 00 02 53 20    //1 frame
				];

				qcom,mdss-dsi-off-command= [
					/* AOD off */
					39 01 00 00 00 00 03 F0 5A 5A
					15 01 00 00 00 00 02 91 02
					15 01 00 00 00 00 02 53 20
					39 01 00 00 00 00 03 F0 A5 A5
					05 01 00 00 0B 00 01 28
					05 01 00 00 80 00 01 10];
				qcom,mdss-dsi-post-on-backlight = [
					/* Display On */
					05 01 00 00 00 00 01 29
				];
				qcom,mdss-dsi-hbm-on-command = [
					39 01 00 00 00 00 03 F0 5A 5A
					39 01 00 00 0D 00 03 51 07 FF
					39 01 00 00 00 00 03 91 02 00
					39 01 00 00 00 00 03 B0 02 90
					39 01 00 00 00 00 02 90 1C
					/* HBM Mode ON */
					39 01 00 00 00 00 02 53 E0
					39 01 00 00 00 00 03 51 0F FF
					39 01 00 00 00 00 03 F0 A5 A5
				];
				qcom,mdss-dsi-normal-hbm-on-command = [
					39 01 00 00 00 00 03 F0 5A 5A
					39 01 00 00 0D 00 03 51 07 FF
					39 01 00 00 00 00 03 91 02 00
					39 01 00 00 00 00 03 B0 02 90
					39 01 00 00 00 00 02 90 1C
					/* HBM Mode ON */
					39 01 00 00 00 00 02 53 E0
					39 01 00 00 00 00 03 51 0F FF
					39 01 00 00 00 00 03 F0 A5 A5
				];
				qcom,mdss-dsi-hbm-off-command = [
					39 01 00 00 00 00 03 F0 5A 5A
					15 01 00 00 00 00 02 53 20
					39 01 00 00 0D 00 03 51 07 FF
					39 01 00 00 00 00 03 91 02 01
					39 01 00 00 00 00 03 B0 02 90
					39 01 00 00 00 00 02 90 18
					39 01 00 00 00 00 03 F0 A5 A5
				];
				qcom,mdss-dsi-aod-hbm-on-command = [
					39 01 00 00 00 00 03 F0 5A 5A
                                        15 01 00 00 00 00 02 91 02
                                        39 01 00 00 00 00 02 53 20
                                        39 01 00 00 00 00 03 F0 A5 A5
					39 01 00 00 00 00 03 F0 5A 5A
					39 01 00 00 0D 00 03 51 07 FF
					39 01 00 00 00 00 03 91 02 00
					39 01 00 00 00 00 03 B0 02 90
					39 01 00 00 00 00 02 90 1C
					/* HBM Mode ON */
					39 01 00 00 00 00 02 53 E0
					39 01 00 00 00 00 03 51 0F FF
					39 01 00 00 00 00 03 F0 A5 A5
				];
				qcom,mdss-dsi-aod-hbm-off-command = [
					39 01 00 00 00 00 03 F0 5A 5A
					15 01 00 00 00 00 02 91 02 
					15 01 00 00 00 00 02 53 20
					39 01 00 00 00 00 03 F0 A5 A5
					39 01 00 00 00 00 03 F0 5A 5A
					15 01 00 00 00 00 02 53 20
					39 01 00 00 0D 00 03 51 07 FF
					39 01 00 00 00 00 03 91 02 01
					39 01 00 00 00 00 03 B0 02 90
					39 01 00 00 00 00 02 90 18
					39 01 00 00 00 00 03 F0 A5 A5
				];
				qcom,mdss-dsi-aod-high-mode-command = [
					/* AOD 50nit */
					39 01 00 00 00 00 03 F0 5A 5A
					15 01 00 00 00 00 02 91 01
					15 01 00 00 00 00 02 53 24
					15 01 00 00 00 00 02 BB 1D
					39 01 00 00 00 00 03 F0 A5 A5
				];
				qcom,mdss-dsi-aod-low-mode-command = [
					/* AOD 10nit */
					39 01 00 00 00 00 03 F0 5A 5A
					15 01 00 00 00 00 02 91 01
					15 01 00 00 00 00 02 53 25
					15 01 00 00 00 00 02 BB 1D
					39 01 00 00 00 00 03 F0 A5 A5
				];
				qcom,mdss-dsi-lp1-command = [
					//05 01 00 00 25 00 01 28
					/*AOD on */
					39 01 00 00 00 00 03 F0 5A 5A
					15 01 00 00 00 00 02 91 01
					15 01 00 00 00 00 02 53 24
					15 01 00 00 00 00 02 BB 1D
					39 01 00 00 00 00 03 F0 A5 A5
				];
				qcom,mdss-dsi-nolp-command = [
					/* AOD off to normal*/
					39 01 00 00 00 00 03 F0 5A 5A
					15 01 00 00 00 00 02 91 02
					15 01 00 00 00 00 02 53 20
					39 01 00 00 00 00 03 F0 A5 A5
				];
                                qcom,mdss-dsi-seed-off-command = [
                                        /* CRC OFF */
                                        39 01 00 00 00 00 03 F0 5A 5A
                                        15 01 00 00 00 00 02 5D 00
                                        15 01 00 00 00 00 02 62 01
                                        39 01 00 00 00 00 03 F0 A5 A5
                                ];
				qcom,mdss-dsi-seed-3-command = [
					39 01 00 00 00 00 03 F0 5A 5A
					39 01 00 00 00 00 03 B0 03 8F
					39 01 00 00 00 00 02 8F 25
					39 01 00 00 00 00 03 B0 28 F2
					39 01 00 00 00 00 02 F2 CE
					39 01 00 00 00 00 04 B0 01 18 68
					39 01 00 00 00 00 0F 68 E2 1A 1A 1A 82 04 F0 80 00 00 00 00 FF 00
					39 01 00 00 00 00 04 B0 00 28 F2
					39 01 00 00 00 00 02 F2 C6
					39 01 00 00 00 00 03 F0 A5 A5
					39 01 00 00 00 00 03 F0 5A 5A
					39 01 00 00 00 00 04 72 2C 21 00
					39 01 00 00 00 00 02 F8 00
					39 01 00 00 00 00 02 5D 06
					39 01 00 00 00 00 02 62 00
					39 01 00 00 00 00 03 B0 01 62
					39 01 00 00 00 00 16 62 D3 01 00 19 Fd 00 0B 04 E2 21 E5 E4 de 06 Ec FA FD 01 FF FF FF
					39 01 00 00 18 00 04 72 2C 01 00
					39 01 00 00 00 00 03 F0 A5 A5
				];
				qcom,mdss-dsi-seed-2-command = [
					39 01 00 00 00 00 03 F0 5A 5A
					39 01 00 00 00 00 03 B0 03 8F
					39 01 00 00 00 00 02 8F 05
					39 01 00 00 00 00 03 B0 28 F2
					39 01 00 00 00 00 02 F2 CE
					39 01 00 00 00 00 04 B0 01 18 68
					39 01 00 00 00 00 0F 68 E2 1A 1A 1A 82 04 F0 80 00 00 00 00 FF 00
					39 01 00 00 00 00 04 B0 00 28 F2
					39 01 00 00 00 00 02 F2 C6
					39 01 00 00 00 00 03 F0 A5 A5
					39 01 00 00 00 00 03 F0 5A 5A
					39 01 00 00 00 00 04 72 2C 21 00
					39 01 00 00 00 00 02 F8 00
					39 01 00 00 00 00 02 5D 06
					39 01 00 00 00 00 02 62 00
					39 01 00 00 00 00 03 B0 01 62
					39 01 00 00 00 00 16 62 FF 00 00 00 FF 00 00 00 FF 00 FF FF FF 00 FF FF FF 00 FF FF FF
					39 01 00 00 18 00 04 72 2C 01 00
					39 01 00 00 00 00 03 F0 A5 A5
				];
				qcom,mdss-dsi-seed-1-command = [
					39 01 00 00 00 00 03 F0 5A 5A
					39 01 00 00 00 00 03 B0 03 8F
					39 01 00 00 00 00 02 8F 25
					39 01 00 00 00 00 03 B0 28 F2
					39 01 00 00 00 00 02 F2 CE
					39 01 00 00 00 00 04 B0 01 18 68
					39 01 00 00 00 00 0F 68 E2 1A 1A 1A 82 04 F0 80 00 00 00 00 FF 00
					39 01 00 00 00 00 04 B0 00 28 F2
					39 01 00 00 00 00 02 F2 C6
					39 01 00 00 00 00 03 F0 A5 A5
					39 01 00 00 00 00 03 F0 5A 5A
					39 01 00 00 00 00 04 72 2C 21 00
					39 01 00 00 00 00 02 F8 00
					39 01 00 00 00 00 02 5D 06
					39 01 00 00 00 00 02 62 00
					39 01 00 00 00 00 03 B0 01 62
					39 01 00 00 00 00 16 62 D3 01 00 19 Fd 00 0B 04 E2 21 E5 E4 de 06 Ec FA FD 01 FF FF FF
					39 01 00 00 18 00 04 72 2C 01 00
					39 01 00 00 00 00 03 F0 A5 A5
				];
				qcom,mdss-dsi-seed-0-command = [
					39 01 00 00 00 00 03 F0 5A 5A
					39 01 00 00 00 00 03 B0 03 8F
					39 01 00 00 00 00 02 8F 05
					39 01 00 00 00 00 03 B0 28 F2
					39 01 00 00 00 00 02 F2 CE
					39 01 00 00 00 00 04 B0 01 18 68
					39 01 00 00 00 00 0F 68 E2 1A 1A 1A 82 04 F0 80 00 00 00 00 FF 90
					39 01 00 00 00 00 04 B0 00 28 F2
					39 01 00 00 00 00 02 F2 C6
					39 01 00 00 00 00 03 F0 A5 A5
					39 01 00 00 00 00 03 F0 5A 5A
					39 01 00 00 00 00 04 72 2C 21 00
					39 01 00 00 00 00 02 F8 00
					39 01 00 00 00 00 02 5D 06
					39 01 00 00 00 00 02 62 00
					39 01 00 00 00 00 03 B0 01 62
					39 01 00 00 00 00 16 62 E5 02 00 1E F2 04 0B 06 E5 28 F3 F7 F8 08 FF EA F4 02 FF FF FF
					39 01 00 00 18 00 04 72 2C 01 00
					39 01 00 00 00 00 03 F0 A5 A5
				];
				qcom,mdss-dsi-seed-0-switch-command = [
					39 01 00 00 00 00 03 F0 5A 5A
					39 01 00 00 00 00 03 B0 03 8F
					39 01 00 00 00 00 02 8F 05
					39 01 00 00 00 00 03 B0 28 F2
					39 01 00 00 00 00 02 F2 CE
					39 01 00 00 00 00 04 B0 01 18 68
					39 01 00 00 00 00 0F 68 E2 1A 1A 1A 82 04 F0 80 00 00 00 00 FF 00
					39 01 00 00 00 00 04 B0 00 28 F2
					39 01 00 00 00 00 02 F2 C6
					39 01 00 00 00 00 03 F0 A5 A5
					39 01 00 00 00 00 03 F0 5A 5A
					39 01 00 00 00 00 04 72 2C 21 00
					39 01 00 00 00 00 02 F8 00
					39 01 00 00 00 00 02 5D 06
					39 01 00 00 00 00 02 62 00
					39 01 00 00 00 00 03 B0 01 62
					39 01 00 00 00 00 16 62 FF 00 00 00 FF 00 00 00 FF 00 FF FF FF 00 FF FF FF 00 FA FA FF
					39 01 00 00 14 00 04 72 2C 01 00
					39 01 00 00 00 00 03 F0 A5 A5
				];
                                qcom,mdss-dsi-seed-1-switch-command = [
					39 01 00 00 00 00 03 F0 5A 5A
					39 01 00 00 00 00 03 B0 03 8F
					39 01 00 00 00 00 02 8F 25
					39 01 00 00 00 00 03 B0 28 F2
					39 01 00 00 00 00 02 F2 CE
					39 01 00 00 00 00 04 B0 01 18 68
					39 01 00 00 00 00 0F 68 E2 1A 1A 1A 82 04 F0 80 00 00 00 00 FF 00
					39 01 00 00 00 00 04 B0 00 28 F2
					39 01 00 00 00 00 02 F2 C6
					39 01 00 00 00 00 03 F0 A5 A5
					39 01 00 00 00 00 03 F0 5A 5A
					39 01 00 00 00 00 04 72 2C 21 00
					39 01 00 00 00 00 02 F8 00
					39 01 00 00 00 00 02 5D 06
					39 01 00 00 00 00 02 62 00
					39 01 00 00 00 00 03 B0 01 62
					39 01 00 00 00 00 16 62 CA 0B 06 40 E9 13 0A 03 B0 48 F2 DC C4 07 C8 E9 E9 1D FA FA FF
					39 01 00 00 14 00 04 72 2C 01 00
					39 01 00 00 00 00 03 F0 A5 A5
                                ];
                                qcom,mdss-dsi-seed-2-switch-command = [
					39 01 00 00 00 00 03 F0 5A 5A
					39 01 00 00 00 00 03 B0 03 8F
					39 01 00 00 00 00 02 8F 05
					39 01 00 00 00 00 03 B0 28 F2
					39 01 00 00 00 00 02 F2 CE
					39 01 00 00 00 00 04 B0 01 18 68
					39 01 00 00 00 00 0F 68 E2 1A 1A 1A 82 04 F0 80 00 00 00 00 FF 90
					39 01 00 00 00 00 04 B0 00 28 F2
					39 01 00 00 00 00 02 F2 C6
					39 01 00 00 00 00 03 F0 A5 A5
					39 01 00 00 00 00 03 F0 5A 5A
					39 01 00 00 00 00 04 72 2C 21 00
					39 01 00 00 00 00 02 F8 00
					39 01 00 00 00 00 02 5D 06
					39 01 00 00 00 00 02 62 00
					39 01 00 00 00 00 03 B0 01 62
					39 01 00 00 00 00 16 62 D7 02 00 1E EA 04 0D 05 C8 28 F3 F7 F8 08 FF EA F4 02 FA FA FF
					39 01 00 00 14 00 04 72 2C 01 00
					39 01 00 00 00 00 03 F0 A5 A5
                                ];
				qcom,mdss-dsi-seed-0-dc-command = [
					39 01 00 00 00 00 03 F0 5A 5A
					39 01 00 00 00 00 03 B0 03 8F
					39 01 00 00 00 00 02 8F 05
					39 01 00 00 00 00 03 B0 28 F2
					39 01 00 00 00 00 02 F2 CE
					39 01 00 00 00 00 04 B0 01 18 68
					39 01 00 00 00 00 0F 68 E2 1A 1A 1A 82 04 F0 80 00 00 00 00 FF 90
					39 01 00 00 00 00 04 B0 00 28 F2
					39 01 00 00 00 00 02 F2 C6
					39 01 00 00 00 00 03 F0 A5 A5
                                        /* SEED CRC Setting Adobe*/
                                        39 01 00 00 00 00 03 F0 5A 5A
					39 01 00 00 00 00 02 5D 06
					39 01 00 00 00 00 02 62 00
					39 01 00 00 00 00 03 B0 01 62
					39 01 00 00 00 00 16 62 FF 00 00 00 FF 00 00 00 FF 00 FF FF FF 00 FF FF FF 00 FF FF FF
                                        39 01 00 00 00 00 03 F0 A5 A5
                                ];
                                qcom,mdss-dsi-seed-1-dc-command = [
					39 01 00 00 00 00 03 F0 5A 5A
					39 01 00 00 00 00 03 B0 03 8F
					39 01 00 00 00 00 02 8F 25
					39 01 00 00 00 00 03 B0 28 F2
					39 01 00 00 00 00 02 F2 CE
					39 01 00 00 00 00 04 B0 01 18 68
					39 01 00 00 00 00 0F 68 E2 1A 1A 1A 82 04 F0 80 00 00 00 00 FF 90
					39 01 00 00 00 00 04 B0 00 28 F2
					39 01 00 00 00 00 02 F2 C6
					39 01 00 00 00 00 03 F0 A5 A5
                                        /* SEED CRC Setting SRGB*/
                                        39 01 00 00 00 00 03 F0 5A 5A
                                        39 01 00 00 00 00 02 5D 06              /* SRGB */
                                        /* SEED CRC ON */
                                        39 01 00 00 00 00 02 62 00
                                        /* SEED CRC Adobe */
                                        39 01 00 00 00 00 03 B0 01 62
					39 01 00 00 00 00 16 62 CA 0B 06 40 E9 13 0A 03 B0 48 F2 DC C4 07 C8 E9 E9 1D FF FF FF
                                        39 01 00 00 00 00 03 F0 A5 A5
                                ];
                                qcom,mdss-dsi-seed-2-dc-command = [
					39 01 00 00 00 00 03 F0 5A 5A
					39 01 00 00 00 00 03 B0 03 8F
					39 01 00 00 00 00 02 8F 05
					39 01 00 00 00 00 03 B0 28 F2
					39 01 00 00 00 00 02 F2 CE
					39 01 00 00 00 00 04 B0 01 18 68
					39 01 00 00 00 00 0F 68 E2 1A 1A 1A 82 04 F0 80 00 00 00 00 FF 90
					39 01 00 00 00 00 04 B0 00 28 F2
					39 01 00 00 00 00 02 F2 C6
					39 01 00 00 00 00 03 F0 A5 A5
                                        /* SEED CRC Setting P3*/
                                        39 01 00 00 00 00 03 F0 5A 5A
					39 01 00 00 00 00 02 5D 06
					39 01 00 00 00 00 02 62 00
					39 01 00 00 00 00 03 B0 01 62
					39 01 00 00 00 00 16 62 D7 02 00 1E EA 04 0D 05 C8 28 F3 F7 F8 08 FF EA F4 02 FF FF FF
                                        39 01 00 00 00 00 03 F0 A5 A5
                                ];
				qcom,mdss-dsi-seed-0-dc-switch-command = [
					39 01 00 00 00 00 03 F0 5A 5A
					39 01 00 00 00 00 03 B0 03 8F
					39 01 00 00 00 00 02 8F 05
					39 01 00 00 00 00 03 B0 28 F2
					39 01 00 00 00 00 02 F2 CE
					39 01 00 00 00 00 04 B0 01 18 68
					39 01 00 00 00 00 0F 68 E2 1A 1A 1A 82 04 F0 80 00 00 00 00 FF 00
					39 01 00 00 00 00 04 B0 00 28 F2
					39 01 00 00 00 00 02 F2 C6
					39 01 00 00 00 00 03 F0 A5 A5
					39 01 00 00 00 00 03 F0 5A 5A
					39 01 00 00 00 00 04 72 2C 21 00
					39 01 00 00 00 00 02 F8 00
					39 01 00 00 00 00 02 5D 06
					39 01 00 00 00 00 02 62 00
					39 01 00 00 00 00 03 B0 01 62
					39 01 00 00 00 00 16 62 FF 00 00 00 FF 00 00 00 FF 00 FF FF FF 00 FF FF FF 00 FF FF FF
					39 01 00 00 14 00 04 72 2C 01 00
					39 01 00 00 00 00 03 F0 A5 A5
                                ];
                                qcom,mdss-dsi-seed-1-dc-switch-command = [
					39 01 00 00 00 00 03 F0 5A 5A
					39 01 00 00 00 00 03 B0 03 8F
					39 01 00 00 00 00 02 8F 25
					39 01 00 00 00 00 03 B0 28 F2
					39 01 00 00 00 00 02 F2 CE
					39 01 00 00 00 00 04 B0 01 18 68
					39 01 00 00 00 00 0F 68 E2 1A 1A 1A 82 04 F0 80 00 00 00 00 FF 00
					39 01 00 00 00 00 04 B0 00 28 F2
					39 01 00 00 00 00 02 F2 C6
					39 01 00 00 00 00 03 F0 A5 A5
					39 01 00 00 00 00 03 F0 5A 5A
					39 01 00 00 00 00 04 72 2C 21 00
					39 01 00 00 00 00 02 F8 00
					39 01 00 00 00 00 02 5D 06
					39 01 00 00 00 00 02 62 00
					39 01 00 00 00 00 03 B0 01 62
					39 01 00 00 00 00 16 62 CA 0B 06 40 E9 13 0A 03 B0 48 F2 DC C4 07 C8 E9 E9 1D FF FF FF
					39 01 00 00 14 00 04 72 2C 01 00
					39 01 00 00 00 00 03 F0 A5 A5
                                ];
                                qcom,mdss-dsi-seed-2-dc-switch-command = [
					39 01 00 00 00 00 03 F0 5A 5A
					39 01 00 00 00 00 03 B0 03 8F
					39 01 00 00 00 00 02 8F 05
					39 01 00 00 00 00 03 B0 28 F2
					39 01 00 00 00 00 02 F2 CE
					39 01 00 00 00 00 04 B0 01 18 68
					39 01 00 00 00 00 0F 68 E2 1A 1A 1A 82 04 F0 80 00 00 00 00 FF 90
					39 01 00 00 00 00 04 B0 00 28 F2
					39 01 00 00 00 00 02 F2 C6
					39 01 00 00 00 00 03 F0 A5 A5
					39 01 00 00 00 00 03 F0 5A 5A
					39 01 00 00 00 00 04 72 2C 21 00
					39 01 00 00 00 00 02 F8 00
					39 01 00 00 00 00 02 5D 06
					39 01 00 00 00 00 02 62 00
					39 01 00 00 00 00 03 B0 01 62
					39 01 00 00 00 00 16 62 D7 02 00 1E EA 04 0D 05 C8 28 F3 F7 F8 08 FF EA F4 02 FF FF FF
					39 01 00 00 14 00 04 72 2C 01 00
					39 01 00 00 00 00 03 F0 A5 A5
                                ];
				qcom,mdss-dsi-hbm-enter-switch-command = [
					39 01 00 00 00 00 03 F0 5A 5A
                                        39 01 00 00 0D 00 03 51 07 FF
                                        39 01 00 00 00 00 03 91 02 00
                                        39 01 00 00 00 00 03 B0 02 90
                                        39 01 00 00 00 00 02 90 1C
                                        /* HBM Mode ON */
                                        39 01 00 00 00 00 02 53 E0
                                        39 01 00 00 00 00 03 F0 A5 A5
				];
				qcom,mdss-dsi-hbm-exit-switch-command = [
					39 01 00 00 00 00 03 F0 5A 5A
                                        15 01 00 00 00 00 02 53 20
                                        39 01 00 00 0D 00 03 51 07 FF
                                        39 01 00 00 00 00 03 91 02 01
                                        39 01 00 00 00 00 03 B0 02 90
                                        39 01 00 00 00 00 02 90 18
                                        39 01 00 00 00 00 03 F0 A5 A5
				];
				qcom,mdss-dsi-osc-clk-mode0-command = [
					/*OSC 415 + 180.3*/
					39 01 00 00 00 00 03 F0 5A 5A
					39 01 00 00 00 00 03 FC 5A 5A
					39 01 00 00 00 00 03 B0 2A C5
					39 01 00 00 00 00 05 C5 0D 10 80 45
					39 01 00 00 00 00 03 B0 2E C5
					39 01 00 00 00 00 03 C5 6F 39
					39 01 00 00 00 00 03 F0 A5 A5
					39 01 00 00 00 00 03 FC A5 A5
				];
				qcom,mdss-dsi-osc-clk-mode1-command = [
					/*OSC 400 + 182.3*/
					39 01 00 00 00 00 03 F0 5A 5A
					39 01 00 00 00 00 03 FC 5A 5A
					39 01 00 00 00 00 03 B0 2A C5
					39 01 00 00 00 00 05 C5 0D 10 80 45
					39 01 00 00 00 00 03 B0 2E C5
					39 01 00 00 00 00 03 C5 70 74
					39 01 00 00 00 00 03 F0 A5 A5
					39 01 00 00 00 00 03 FC A5 A5
				];
				qcom,mdss-dsi-osc-clk-mode2-command = [
					/*OSC 400 + 180.3*/
					39 01 00 00 00 00 03 F0 5A 5A
					39 01 00 00 00 00 03 FC 5A 5A
					39 01 00 00 00 00 03 B0 2A C5
					39 01 00 00 00 00 05 C5 0D 10 80 45
					39 01 00 00 00 00 03 B0 2E C5
					39 01 00 00 00 00 03 C5 73 64
					39 01 00 00 00 00 03 F0 A5 A5
					39 01 00 00 00 00 03 FC A5 A5
				];
				qcom,mdss-dsi-osc-clk-mode3-command = [
					/*OSC 400 + 182.3*/
					39 01 00 00 00 00 03 F0 5A 5A
					39 01 00 00 00 00 03 FC 5A 5A
					39 01 00 00 00 00 03 B0 2A C5
					39 01 00 00 00 00 05 C5 0D 10 80 45
					39 01 00 00 00 00 03 B0 2E C5
					39 01 00 00 00 00 03 C5 74 AC
					39 01 00 00 00 00 03 F0 A5 A5
					39 01 00 00 00 00 03 FC A5 A5
				];
				qcom,mdss-dsi-timing-switch-command-state = "dsi_hs_mode";
				qcom,mdss-dsi-on-command-state = "dsi_lp_mode";
				qcom,mdss-dsi-fps-switch-command-state = "dsi_hs_mode";
				qcom,mdss-dsi-off-command-state = "dsi_hs_mode";
				qcom,mdss-dsi-hbm-on-command-state = "dsi_hs_mode";
				qcom,mdss-dsi-hbm-off-command-state = "dsi_hs_mode";
				qcom,mdss-dsi-osc-clk-mode0-command-state = "dsi_hs_mode";
				qcom,mdss-dsi-osc-clk-mode1-command-state = "dsi_hs_mode";
				qcom,mdss-dsi-osc-clk-mode2-command-state = "dsi_hs_mode";
				qcom,mdss-dsi-osc-clk-mode3-command-state = "dsi_hs_mode";
				qcom,mdss-dsi-seed-0-command-state = "dsi_hs_mode";
				qcom,mdss-dsi-seed-1-command-state = "dsi_hs_mode";
				qcom,mdss-dsi-seed-2-command-state = "dsi_hs_mode";
				qcom,mdss-dsi-seed-3-command-state = "dsi_hs_mode";
				qcom,mdss-dsi-seed-0-dc-command-state = "dsi_hs_mode";
				qcom,mdss-dsi-seed-1-dc-command-state = "dsi_hs_mode";
				qcom,mdss-dsi-seed-2-dc-command-state = "dsi_hs_mode";
				qcom,mdss-dsi-seed-0-dc-switch-command-state = "dsi_hs_mode";
				qcom,mdss-dsi-seed-1-dc-switch-command-state = "dsi_hs_mode";
				qcom,mdss-dsi-seed-2-dc-switch-command-state = "dsi_hs_mode";
				qcom,mdss-dsi-seed-0-switch-command-state = "dsi_hs_mode";
				qcom,mdss-dsi-seed-1-switch-command-state = "dsi_hs_mode";
				qcom,mdss-dsi-seed-2-switch-command-state = "dsi_hs_mode";
				qcom,mdss-dsi-seed-off-command-state = "dsi_hs_mode";
				qcom,compression-mode = "dsc";
				qcom,mdss-dsc-slice-height = <30>;
				qcom,mdss-dsc-slice-width = <540>;
				qcom,mdss-dsc-slice-per-pkt = <2>;
				qcom,mdss-dsc-bit-per-component = <8>;
				qcom,mdss-dsc-bit-per-pixel = <8>;
				qcom,mdss-dsc-block-prediction-enable;
			};
		};
	};
};

&dsi_oplus21623samsung_ams662zs01_1080_2400_cmd {
	qcom,panel-supply-entries = <&dsi_panel_pwr_supply>;
	qcom,mdss-dsi-panel-controller = <&mdss_dsi0>;
	qcom,mdss-dsi-bl-pmic-control-type = "bl_ctrl_dcs";
	qcom,mdss-dsi-bl-min-level = <1>;
	qcom,mdss-dsi-bl-normal-max-level = <2047>;
	qcom,mdss-dsi-bl-max-level = <4095>;
	qcom,mdss-brightness-normal-max-level = <2047>;
	qcom,mdss-brightness-max-level = <4095>;
	qcom,mdss-brightness-default-level = <400>;
	qcom,platform-te-gpio = <&tlmm 66 0>;
	qcom,platform-reset-gpio = <&tlmm 75 0>;
	qcom,platform-panel-vout-gpio = <&tlmm 125 0>;
//	qcom,platform-panel-vddr-aod-en-gpio = <&tlmm 125 0>;
	qcom,mdss-dsi-reset-sequence = <1 10>, <0 2>, <1 5>;
	qcom,ulps-enabled;
	qcom,dsi-dyn-clk-enable;
	qcom,dsi-dyn-clk-list = <800000000 830000000>;
	qcom,dsi-select-clocks = "mux_byte_clk0", "mux_pixel_clk0",
						"src_byte_clk0", "src_pixel_clk0",
						"shadow_byte_clk0", "shadow_pixel_clk0";
	oplus,osc-support;
	oplus,mdss-dsi-osc-clk-mode0-rate = <180300>;
	oplus,mdss-dsi-osc-clk-mode1-rate = <182300>;
	oplus,osc-rewrite-support;
	oplus,mdss-dsi-osc-rewrite-rate = <800000000>;
	qcom,mdss-dsi-dc-backlight-level = <1100>;
	oplus,apollo-sync-brightness-level = <711>;
	oplus,dc_apollo_sync_enable;
	oplus,dc-apollo-backlight-sync-level = <1100>;
	oplus,dc-apollo-backlight-sync-level-pcc-max = <32760>;
	oplus,dc-apollo-backlight-sync-level-pcc-min = <21600>;
	oplus,dsi-fod-brightness = <0 255>,
                                <4 238>,
				<256 229>,
                                <266 228>,
                                <340 220>,
                                <430 210>,
                                <506 202>,
                                <580 194>,
                                <710 184>,
                                <750 176>,
                                <790 171>,
                                <852 165>,
                                <894 160>,
                                <982 152>,
                                <1052 146>,
                                <1120 139>,
                                <1178 133>,
                                <1224 128>,
                                <1292 121>,
                                <1344 116>,
                                <1392 111>,
                                <1430 106>,
                                <1500 99>,
                                <1554 94>,
                                <1590 89>,
                                <1648 83>,
                                <1674 80>,
                                <1732 74>,
                                <1778 69>,
                                <1828 64>,
                                <1856 61>,
                                <1880 58>,
                                <1894 56>,
				<1956 50>,
				<2006 44>,
                                <2047 40>;

	oplus,dsi-dc-brightness = <0 255>,
			<1 255>,
			<4 248>,
			<8 247>,
			<35 245>,
			<105 243>,
			<195 240>,
			<235 238>,
			<305 233>,
			<400 225>,
			<500 215>,
			<580 205>,
			<591 195>,
			<660 175>,
			<720 155>,
			<780 135>,
			<825 115>,
			<865 95>,
			<900 76>,
			<963 55>,
			<1000 38>,
			<1050 18>,
			<1100 0>;
/*
	oplus,dsi-brightness-remapping = <4    4>,
			<5    5>,
			<6    6>,
			<7    7>,
			<10   10>,
			<244  19>,
			<373  49>,
			<493  90>,
			<585  130>,
			<663  171>,
			<731  212>,
			<792  253>,
			<847  294>,
			<899  335>,
			<948  376>,
			<993  417>,
			<1036 458>,
			<1078 499>,
			<1117 540>,
			<1155 581>,
			<1191 622>,
			<1226 663>,
			<1260 704>,
			<1293 745>,
			<1325 786>,
			<1356 826>,
			<1386 867>,
			<1415 908>,
			<1444 949>,
			<1472 990>,
			<1499 1031>,
			<1526 1072>,
			<1552 1113>,
			<1578 1154>,
			<1603 1195>,
			<1628 1236>,
			<1652 1277>,
			<1676 1318>,
			<1699 1359>,
			<1722 1400>,
			<1745 1441>,
			<1767 1482>,
			<1789 1522>,
			<1811 1563>,
			<1833 1604>,
			<1854 1645>,
			<1875 1686>,
			<1895 1727>,
			<1915 1768>,
			<1935 1809>,
			<1955 1850>,
			<1975 1891>,
			<1994 1932>,
			<2013 1973>,
			<2032 2014>,
			<2043 2038>,
			<2045 2042>,
			<2047 2047>,
			<4095 4095>;
*/
	qcom,mdss-dsi-display-timings {
		timing@0 {
			qcom,mdss-dsi-panel-phy-timings = [00 1D 07 07 17 16 07 07 08 02 04 00 19 0C];
			 qcom,display-topology = <1 1 1>,<2 2 1>;
			 qcom,default-topology-index = <0>;
		};
		timing@1 {
			qcom,mdss-dsi-panel-phy-timings = [00 1D 07 07 17 22 07 07 08 02 04 00 19 0C];
			 qcom,display-topology = <1 1 1>,<2 2 1>;
			 qcom,default-topology-index = <0>;
		};
		timing@2 {
                        qcom,mdss-dsi-panel-phy-timings = [00 1D 07 07 17 22 07 07 08 02 04 00 19 0C];
                         qcom,display-topology = <1 1 1>,<2 2 1>;
                         qcom,default-topology-index = <0>;
                };
	};
};

&dsi_oplus21623samsung_ams662zs01_1080_2400_cmd {
	oplus,apollo_backlight_enable;
	//oplus,color_srgb_status;
	oplus,bl_interpolate_nosub;
	oplus,90fps_switch;
	oplus,bl_interpolate_remapping_nosub;
	oplus,bl_interpolate_alpha_dc_nosub;
	//oplus,dc_seed_support;
};
